AUTOSAR XML (schema 00050)
package /IBNvBlkSWC_0
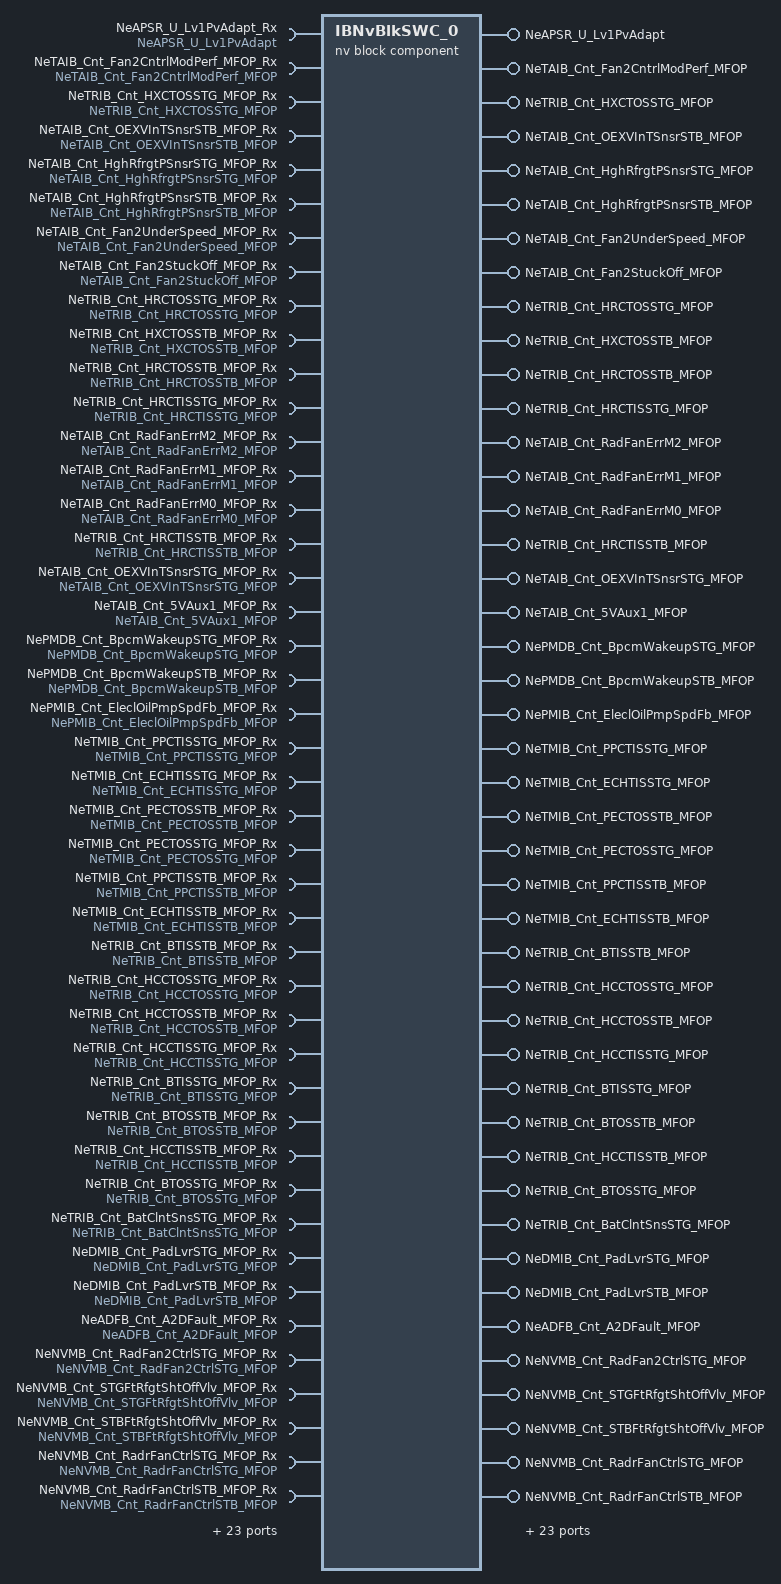
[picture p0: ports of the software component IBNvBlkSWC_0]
  nv block sw component type IBNvBlkSWC_0
    provide port NeAPSR_U_Lv1PvAdapt: nv-provide-com-spec{ram-block-init-value=Value:0, rom-block-init-value=Value:0, variable=NeAPSR_U_Lv1PvAdapt}, provided-interface=NeAPSR_U_Lv1PvAdapt
    require port NeAPSR_U_Lv1PvAdapt_Rx: nv-require-com-spec{init-value=Value:0, variable=NeAPSR_U_Lv1PvAdapt}, required-interface=NeAPSR_U_Lv1PvAdapt
    provide port NeTAIB_Cnt_Fan2CntrlModPerf_MFOP: nv-provide-com-spec{ram-block-init-value=Value:0, rom-block-init-value=Value:0, variable=NeTAIB_Cnt_Fan2CntrlModPerf_MFOP}, provided-interface=NeTAIB_Cnt_Fan2CntrlModPerf_MFOP
    require port NeTAIB_Cnt_Fan2CntrlModPerf_MFOP_Rx: nv-require-com-spec{init-value=Value:0, variable=NeTAIB_Cnt_Fan2CntrlModPerf_MFOP}, required-interface=NeTAIB_Cnt_Fan2CntrlModPerf_MFOP
    provide port NeTRIB_Cnt_HXCTOSSTG_MFOP: nv-provide-com-spec{ram-block-init-value=Value:0, rom-block-init-value=Value:0, variable=NeTRIB_Cnt_HXCTOSSTG_MFOP}, provided-interface=NeTRIB_Cnt_HXCTOSSTG_MFOP
    require port NeTRIB_Cnt_HXCTOSSTG_MFOP_Rx: nv-require-com-spec{init-value=Value:0, variable=NeTRIB_Cnt_HXCTOSSTG_MFOP}, required-interface=NeTRIB_Cnt_HXCTOSSTG_MFOP
    provide port NeTAIB_Cnt_OEXVInTSnsrSTB_MFOP: nv-provide-com-spec{ram-block-init-value=Value:0, rom-block-init-value=Value:0, variable=NeTAIB_Cnt_OEXVInTSnsrSTB_MFOP}, provided-interface=NeTAIB_Cnt_OEXVInTSnsrSTB_MFOP
    require port NeTAIB_Cnt_OEXVInTSnsrSTB_MFOP_Rx: nv-require-com-spec{init-value=Value:0, variable=NeTAIB_Cnt_OEXVInTSnsrSTB_MFOP}, required-interface=NeTAIB_Cnt_OEXVInTSnsrSTB_MFOP
    provide port NeTAIB_Cnt_HghRfrgtPSnsrSTG_MFOP: nv-provide-com-spec{ram-block-init-value=Value:0, rom-block-init-value=Value:0, variable=NeTAIB_Cnt_HghRfrgtPSnsrSTG_MFOP}, provided-interface=NeTAIB_Cnt_HghRfrgtPSnsrSTG_MFOP
    require port NeTAIB_Cnt_HghRfrgtPSnsrSTG_MFOP_Rx: nv-require-com-spec{init-value=Value:0, variable=NeTAIB_Cnt_HghRfrgtPSnsrSTG_MFOP}, required-interface=NeTAIB_Cnt_HghRfrgtPSnsrSTG_MFOP
    provide port NeTAIB_Cnt_HghRfrgtPSnsrSTB_MFOP: nv-provide-com-spec{ram-block-init-value=Value:0, rom-block-init-value=Value:0, variable=NeTAIB_Cnt_HghRfrgtPSnsrSTB_MFOP}, provided-interface=NeTAIB_Cnt_HghRfrgtPSnsrSTB_MFOP
    require port NeTAIB_Cnt_HghRfrgtPSnsrSTB_MFOP_Rx: nv-require-com-spec{init-value=Value:0, variable=NeTAIB_Cnt_HghRfrgtPSnsrSTB_MFOP}, required-interface=NeTAIB_Cnt_HghRfrgtPSnsrSTB_MFOP
    provide port NeTAIB_Cnt_Fan2UnderSpeed_MFOP: nv-provide-com-spec{ram-block-init-value=Value:0, rom-block-init-value=Value:0, variable=NeTAIB_Cnt_Fan2UnderSpeed_MFOP}, provided-interface=NeTAIB_Cnt_Fan2UnderSpeed_MFOP
    require port NeTAIB_Cnt_Fan2UnderSpeed_MFOP_Rx: nv-require-com-spec{init-value=Value:0, variable=NeTAIB_Cnt_Fan2UnderSpeed_MFOP}, required-interface=NeTAIB_Cnt_Fan2UnderSpeed_MFOP
    provide port NeTAIB_Cnt_Fan2StuckOff_MFOP: nv-provide-com-spec{ram-block-init-value=Value:0, rom-block-init-value=Value:0, variable=NeTAIB_Cnt_Fan2StuckOff_MFOP}, provided-interface=NeTAIB_Cnt_Fan2StuckOff_MFOP
    require port NeTAIB_Cnt_Fan2StuckOff_MFOP_Rx: nv-require-com-spec{init-value=Value:0, variable=NeTAIB_Cnt_Fan2StuckOff_MFOP}, required-interface=NeTAIB_Cnt_Fan2StuckOff_MFOP
    provide port NeTRIB_Cnt_HRCTOSSTG_MFOP: nv-provide-com-spec{ram-block-init-value=Value:0, rom-block-init-value=Value:0, variable=NeTRIB_Cnt_HRCTOSSTG_MFOP}, provided-interface=NeTRIB_Cnt_HRCTOSSTG_MFOP
    require port NeTRIB_Cnt_HRCTOSSTG_MFOP_Rx: nv-require-com-spec{init-value=Value:0, variable=NeTRIB_Cnt_HRCTOSSTG_MFOP}, required-interface=NeTRIB_Cnt_HRCTOSSTG_MFOP
    provide port NeTRIB_Cnt_HXCTOSSTB_MFOP: nv-provide-com-spec{ram-block-init-value=Value:0, rom-block-init-value=Value:0, variable=NeTRIB_Cnt_HXCTOSSTB_MFOP}, provided-interface=NeTRIB_Cnt_HXCTOSSTB_MFOP
    require port NeTRIB_Cnt_HXCTOSSTB_MFOP_Rx: nv-require-com-spec{init-value=Value:0, variable=NeTRIB_Cnt_HXCTOSSTB_MFOP}, required-interface=NeTRIB_Cnt_HXCTOSSTB_MFOP
    provide port NeTRIB_Cnt_HRCTOSSTB_MFOP: nv-provide-com-spec{ram-block-init-value=Value:0, rom-block-init-value=Value:0, variable=NeTRIB_Cnt_HRCTOSSTB_MFOP}, provided-interface=NeTRIB_Cnt_HRCTOSSTB_MFOP
    require port NeTRIB_Cnt_HRCTOSSTB_MFOP_Rx: nv-require-com-spec{init-value=Value:0, variable=NeTRIB_Cnt_HRCTOSSTB_MFOP}, required-interface=NeTRIB_Cnt_HRCTOSSTB_MFOP
    provide port NeTRIB_Cnt_HRCTISSTG_MFOP: nv-provide-com-spec{ram-block-init-value=Value:0, rom-block-init-value=Value:0, variable=NeTRIB_Cnt_HRCTISSTG_MFOP}, provided-interface=NeTRIB_Cnt_HRCTISSTG_MFOP
    require port NeTRIB_Cnt_HRCTISSTG_MFOP_Rx: nv-require-com-spec{init-value=Value:0, variable=NeTRIB_Cnt_HRCTISSTG_MFOP}, required-interface=NeTRIB_Cnt_HRCTISSTG_MFOP
    provide port NeTAIB_Cnt_RadFanErrM2_MFOP: nv-provide-com-spec{ram-block-init-value=Value:0, rom-block-init-value=Value:0, variable=NeTAIB_Cnt_RadFanErrM2_MFOP}, provided-interface=NeTAIB_Cnt_RadFanErrM2_MFOP
    require port NeTAIB_Cnt_RadFanErrM2_MFOP_Rx: nv-require-com-spec{init-value=Value:0, variable=NeTAIB_Cnt_RadFanErrM2_MFOP}, required-interface=NeTAIB_Cnt_RadFanErrM2_MFOP
    provide port NeTAIB_Cnt_RadFanErrM1_MFOP: nv-provide-com-spec{ram-block-init-value=Value:0, rom-block-init-value=Value:0, variable=NeTAIB_Cnt_RadFanErrM1_MFOP}, provided-interface=NeTAIB_Cnt_RadFanErrM1_MFOP
    require port NeTAIB_Cnt_RadFanErrM1_MFOP_Rx: nv-require-com-spec{init-value=Value:0, variable=NeTAIB_Cnt_RadFanErrM1_MFOP}, required-interface=NeTAIB_Cnt_RadFanErrM1_MFOP
    provide port NeTAIB_Cnt_RadFanErrM0_MFOP: nv-provide-com-spec{ram-block-init-value=Value:0, rom-block-init-value=Value:0, variable=NeTAIB_Cnt_RadFanErrM0_MFOP}, provided-interface=NeTAIB_Cnt_RadFanErrM0_MFOP
    require port NeTAIB_Cnt_RadFanErrM0_MFOP_Rx: nv-require-com-spec{init-value=Value:0, variable=NeTAIB_Cnt_RadFanErrM0_MFOP}, required-interface=NeTAIB_Cnt_RadFanErrM0_MFOP
    provide port NeTRIB_Cnt_HRCTISSTB_MFOP: nv-provide-com-spec{ram-block-init-value=Value:0, rom-block-init-value=Value:0, variable=NeTRIB_Cnt_HRCTISSTB_MFOP}, provided-interface=NeTRIB_Cnt_HRCTISSTB_MFOP
    require port NeTRIB_Cnt_HRCTISSTB_MFOP_Rx: nv-require-com-spec{init-value=Value:0, variable=NeTRIB_Cnt_HRCTISSTB_MFOP}, required-interface=NeTRIB_Cnt_HRCTISSTB_MFOP
    provide port NeTAIB_Cnt_OEXVInTSnsrSTG_MFOP: nv-provide-com-spec{ram-block-init-value=Value:0, rom-block-init-value=Value:0, variable=NeTAIB_Cnt_OEXVInTSnsrSTG_MFOP}, provided-interface=NeTAIB_Cnt_OEXVInTSnsrSTG_MFOP
    require port NeTAIB_Cnt_OEXVInTSnsrSTG_MFOP_Rx: nv-require-com-spec{init-value=Value:0, variable=NeTAIB_Cnt_OEXVInTSnsrSTG_MFOP}, required-interface=NeTAIB_Cnt_OEXVInTSnsrSTG_MFOP
    provide port NeTAIB_Cnt_5VAux1_MFOP: nv-provide-com-spec{ram-block-init-value=Value:0, rom-block-init-value=Value:0, variable=NeTAIB_Cnt_5VAux1_MFOP}, provided-interface=NeTAIB_Cnt_5VAux1_MFOP
    require port NeTAIB_Cnt_5VAux1_MFOP_Rx: nv-require-com-spec{init-value=Value:0, variable=NeTAIB_Cnt_5VAux1_MFOP}, required-interface=NeTAIB_Cnt_5VAux1_MFOP
    provide port NePMDB_Cnt_BpcmWakeupSTG_MFOP: nv-provide-com-spec{ram-block-init-value=Value:0, rom-block-init-value=Value:0, variable=NePMDB_Cnt_BpcmWakeupSTG_MFOP}, provided-interface=NePMDB_Cnt_BpcmWakeupSTG_MFOP
    require port NePMDB_Cnt_BpcmWakeupSTG_MFOP_Rx: nv-require-com-spec{init-value=Value:0, variable=NePMDB_Cnt_BpcmWakeupSTG_MFOP}, required-interface=NePMDB_Cnt_BpcmWakeupSTG_MFOP
    provide port NePMDB_Cnt_BpcmWakeupSTB_MFOP: nv-provide-com-spec{ram-block-init-value=Value:0, rom-block-init-value=Value:0, variable=NePMDB_Cnt_BpcmWakeupSTB_MFOP}, provided-interface=NePMDB_Cnt_BpcmWakeupSTB_MFOP
    require port NePMDB_Cnt_BpcmWakeupSTB_MFOP_Rx: nv-require-com-spec{init-value=Value:0, variable=NePMDB_Cnt_BpcmWakeupSTB_MFOP}, required-interface=NePMDB_Cnt_BpcmWakeupSTB_MFOP
    provide port NePMIB_Cnt_EleclOilPmpSpdFb_MFOP: nv-provide-com-spec{ram-block-init-value=Value:0, rom-block-init-value=Value:0, variable=NePMIB_Cnt_EleclOilPmpSpdFb_MFOP}, provided-interface=NePMIB_Cnt_EleclOilPmpSpdFb_MFOP
    require port NePMIB_Cnt_EleclOilPmpSpdFb_MFOP_Rx: nv-require-com-spec{init-value=Value:0, variable=NePMIB_Cnt_EleclOilPmpSpdFb_MFOP}, required-interface=NePMIB_Cnt_EleclOilPmpSpdFb_MFOP
    provide port NeTMIB_Cnt_PPCTISSTG_MFOP: nv-provide-com-spec{ram-block-init-value=Value:0, rom-block-init-value=Value:0, variable=NeTMIB_Cnt_PPCTISSTG_MFOP}, provided-interface=NeTMIB_Cnt_PPCTISSTG_MFOP
    require port NeTMIB_Cnt_PPCTISSTG_MFOP_Rx: nv-require-com-spec{init-value=Value:0, variable=NeTMIB_Cnt_PPCTISSTG_MFOP}, required-interface=NeTMIB_Cnt_PPCTISSTG_MFOP
    provide port NeTMIB_Cnt_ECHTISSTG_MFOP: nv-provide-com-spec{ram-block-init-value=Value:0, rom-block-init-value=Value:0, variable=NeTMIB_Cnt_ECHTISSTG_MFOP}, provided-interface=NeTMIB_Cnt_ECHTISSTG_MFOP
    require port NeTMIB_Cnt_ECHTISSTG_MFOP_Rx: nv-require-com-spec{init-value=Value:0, variable=NeTMIB_Cnt_ECHTISSTG_MFOP}, required-interface=NeTMIB_Cnt_ECHTISSTG_MFOP
    provide port NeTMIB_Cnt_PECTOSSTB_MFOP: nv-provide-com-spec{ram-block-init-value=Value:0, rom-block-init-value=Value:0, variable=NeTMIB_Cnt_PECTOSSTB_MFOP}, provided-interface=NeTMIB_Cnt_PECTOSSTB_MFOP
    require port NeTMIB_Cnt_PECTOSSTB_MFOP_Rx: nv-require-com-spec{init-value=Value:0, variable=NeTMIB_Cnt_PECTOSSTB_MFOP}, required-interface=NeTMIB_Cnt_PECTOSSTB_MFOP
    provide port NeTMIB_Cnt_PECTOSSTG_MFOP: nv-provide-com-spec{ram-block-init-value=Value:0, rom-block-init-value=Value:0, variable=NeTMIB_Cnt_PECTOSSTG_MFOP}, provided-interface=NeTMIB_Cnt_PECTOSSTG_MFOP
    require port NeTMIB_Cnt_PECTOSSTG_MFOP_Rx: nv-require-com-spec{init-value=Value:0, variable=NeTMIB_Cnt_PECTOSSTG_MFOP}, required-interface=NeTMIB_Cnt_PECTOSSTG_MFOP
    provide port NeTMIB_Cnt_PPCTISSTB_MFOP: nv-provide-com-spec{ram-block-init-value=Value:0, rom-block-init-value=Value:0, variable=NeTMIB_Cnt_PPCTISSTB_MFOP}, provided-interface=NeTMIB_Cnt_PPCTISSTB_MFOP
    require port NeTMIB_Cnt_PPCTISSTB_MFOP_Rx: nv-require-com-spec{init-value=Value:0, variable=NeTMIB_Cnt_PPCTISSTB_MFOP}, required-interface=NeTMIB_Cnt_PPCTISSTB_MFOP
    provide port NeTMIB_Cnt_ECHTISSTB_MFOP: nv-provide-com-spec{ram-block-init-value=Value:0, rom-block-init-value=Value:0, variable=NeTMIB_Cnt_ECHTISSTB_MFOP}, provided-interface=NeTMIB_Cnt_ECHTISSTB_MFOP
    require port NeTMIB_Cnt_ECHTISSTB_MFOP_Rx: nv-require-com-spec{init-value=Value:0, variable=NeTMIB_Cnt_ECHTISSTB_MFOP}, required-interface=NeTMIB_Cnt_ECHTISSTB_MFOP
    provide port NeTRIB_Cnt_BTISSTB_MFOP: nv-provide-com-spec{ram-block-init-value=Value:0, rom-block-init-value=Value:0, variable=NeTRIB_Cnt_BTISSTB_MFOP}, provided-interface=NeTRIB_Cnt_BTISSTB_MFOP
    require port NeTRIB_Cnt_BTISSTB_MFOP_Rx: nv-require-com-spec{init-value=Value:0, variable=NeTRIB_Cnt_BTISSTB_MFOP}, required-interface=NeTRIB_Cnt_BTISSTB_MFOP
    provide port NeTRIB_Cnt_HCCTOSSTG_MFOP: nv-provide-com-spec{ram-block-init-value=Value:0, rom-block-init-value=Value:0, variable=NeTRIB_Cnt_HCCTOSSTG_MFOP}, provided-interface=NeTRIB_Cnt_HCCTOSSTG_MFOP
    require port NeTRIB_Cnt_HCCTOSSTG_MFOP_Rx: nv-require-com-spec{init-value=Value:0, variable=NeTRIB_Cnt_HCCTOSSTG_MFOP}, required-interface=NeTRIB_Cnt_HCCTOSSTG_MFOP
    provide port NeTRIB_Cnt_HCCTOSSTB_MFOP: nv-provide-com-spec{ram-block-init-value=Value:0, rom-block-init-value=Value:0, variable=NeTRIB_Cnt_HCCTOSSTB_MFOP}, provided-interface=NeTRIB_Cnt_HCCTOSSTB_MFOP
    require port NeTRIB_Cnt_HCCTOSSTB_MFOP_Rx: nv-require-com-spec{init-value=Value:0, variable=NeTRIB_Cnt_HCCTOSSTB_MFOP}, required-interface=NeTRIB_Cnt_HCCTOSSTB_MFOP
    provide port NeTRIB_Cnt_HCCTISSTG_MFOP: nv-provide-com-spec{ram-block-init-value=Value:0, rom-block-init-value=Value:0, variable=NeTRIB_Cnt_HCCTISSTG_MFOP}, provided-interface=NeTRIB_Cnt_HCCTISSTG_MFOP
    require port NeTRIB_Cnt_HCCTISSTG_MFOP_Rx: nv-require-com-spec{init-value=Value:0, variable=NeTRIB_Cnt_HCCTISSTG_MFOP}, required-interface=NeTRIB_Cnt_HCCTISSTG_MFOP
    provide port NeTRIB_Cnt_BTISSTG_MFOP: nv-provide-com-spec{ram-block-init-value=Value:0, rom-block-init-value=Value:0, variable=NeTRIB_Cnt_BTISSTG_MFOP}, provided-interface=NeTRIB_Cnt_BTISSTG_MFOP
    require port NeTRIB_Cnt_BTISSTG_MFOP_Rx: nv-require-com-spec{init-value=Value:0, variable=NeTRIB_Cnt_BTISSTG_MFOP}, required-interface=NeTRIB_Cnt_BTISSTG_MFOP
    provide port NeTRIB_Cnt_BTOSSTB_MFOP: nv-provide-com-spec{ram-block-init-value=Value:0, rom-block-init-value=Value:0, variable=NeTRIB_Cnt_BTOSSTB_MFOP}, provided-interface=NeTRIB_Cnt_BTOSSTB_MFOP
    require port NeTRIB_Cnt_BTOSSTB_MFOP_Rx: nv-require-com-spec{init-value=Value:0, variable=NeTRIB_Cnt_BTOSSTB_MFOP}, required-interface=NeTRIB_Cnt_BTOSSTB_MFOP
    provide port NeTRIB_Cnt_HCCTISSTB_MFOP: nv-provide-com-spec{ram-block-init-value=Value:0, rom-block-init-value=Value:0, variable=NeTRIB_Cnt_HCCTISSTB_MFOP}, provided-interface=NeTRIB_Cnt_HCCTISSTB_MFOP
    require port NeTRIB_Cnt_HCCTISSTB_MFOP_Rx: nv-require-com-spec{init-value=Value:0, variable=NeTRIB_Cnt_HCCTISSTB_MFOP}, required-interface=NeTRIB_Cnt_HCCTISSTB_MFOP
    provide port NeTRIB_Cnt_BTOSSTG_MFOP: nv-provide-com-spec{ram-block-init-value=Value:0, rom-block-init-value=Value:0, variable=NeTRIB_Cnt_BTOSSTG_MFOP}, provided-interface=NeTRIB_Cnt_BTOSSTG_MFOP
    require port NeTRIB_Cnt_BTOSSTG_MFOP_Rx: nv-require-com-spec{init-value=Value:0, variable=NeTRIB_Cnt_BTOSSTG_MFOP}, required-interface=NeTRIB_Cnt_BTOSSTG_MFOP
    provide port NeTRIB_Cnt_BatClntSnsSTG_MFOP: nv-provide-com-spec{ram-block-init-value=Value:0, rom-block-init-value=Value:0, variable=NeTRIB_Cnt_BatClntSnsSTG_MFOP}, provided-interface=NeTRIB_Cnt_BatClntSnsSTG_MFOP
    require port NeTRIB_Cnt_BatClntSnsSTG_MFOP_Rx: nv-require-com-spec{init-value=Value:0, variable=NeTRIB_Cnt_BatClntSnsSTG_MFOP}, required-interface=NeTRIB_Cnt_BatClntSnsSTG_MFOP
    provide port NeDMIB_Cnt_PadLvrSTG_MFOP: nv-provide-com-spec{ram-block-init-value=Value:0, rom-block-init-value=Value:0, variable=NeDMIB_Cnt_PadLvrSTG_MFOP}, provided-interface=NeDMIB_Cnt_PadLvrSTG_MFOP
    require port NeDMIB_Cnt_PadLvrSTG_MFOP_Rx: nv-require-com-spec{init-value=Value:0, variable=NeDMIB_Cnt_PadLvrSTG_MFOP}, required-interface=NeDMIB_Cnt_PadLvrSTG_MFOP
    provide port NeDMIB_Cnt_PadLvrSTB_MFOP: nv-provide-com-spec{ram-block-init-value=Value:0, rom-block-init-value=Value:0, variable=NeDMIB_Cnt_PadLvrSTB_MFOP}, provided-interface=NeDMIB_Cnt_PadLvrSTB_MFOP
    require port NeDMIB_Cnt_PadLvrSTB_MFOP_Rx: nv-require-com-spec{init-value=Value:0, variable=NeDMIB_Cnt_PadLvrSTB_MFOP}, required-interface=NeDMIB_Cnt_PadLvrSTB_MFOP
    provide port NeADFB_Cnt_A2DFault_MFOP: nv-provide-com-spec{ram-block-init-value=Value:0, rom-block-init-value=Value:0, variable=NeADFB_Cnt_A2DFault_MFOP}, provided-interface=NeADFB_Cnt_A2DFault_MFOP
    require port NeADFB_Cnt_A2DFault_MFOP_Rx: nv-require-com-spec{init-value=Value:0, variable=NeADFB_Cnt_A2DFault_MFOP}, required-interface=NeADFB_Cnt_A2DFault_MFOP
    provide port NeNVMB_Cnt_RadFan2CtrlSTG_MFOP: nv-provide-com-spec{ram-block-init-value=Value:0, rom-block-init-value=Value:0, variable=NeNVMB_Cnt_RadFan2CtrlSTG_MFOP}, provided-interface=NeNVMB_Cnt_RadFan2CtrlSTG_MFOP
    require port NeNVMB_Cnt_RadFan2CtrlSTG_MFOP_Rx: nv-require-com-spec{init-value=Value:0, variable=NeNVMB_Cnt_RadFan2CtrlSTG_MFOP}, required-interface=NeNVMB_Cnt_RadFan2CtrlSTG_MFOP
    provide port NeNVMB_Cnt_STGFtRfgtShtOffVlv_MFOP: nv-provide-com-spec{ram-block-init-value=Value:0, rom-block-init-value=Value:0, variable=NeNVMB_Cnt_STGFtRfgtShtOffVlv_MFOP}, provided-interface=NeNVMB_Cnt_STGFtRfgtShtOffVlv_MFOP
    require port NeNVMB_Cnt_STGFtRfgtShtOffVlv_MFOP_Rx: nv-require-com-spec{init-value=Value:0, variable=NeNVMB_Cnt_STGFtRfgtShtOffVlv_MFOP}, required-interface=NeNVMB_Cnt_STGFtRfgtShtOffVlv_MFOP
    provide port NeNVMB_Cnt_STBFtRfgtShtOffVlv_MFOP: nv-provide-com-spec{ram-block-init-value=Value:0, rom-block-init-value=Value:0, variable=NeNVMB_Cnt_STBFtRfgtShtOffVlv_MFOP}, provided-interface=NeNVMB_Cnt_STBFtRfgtShtOffVlv_MFOP
    require port NeNVMB_Cnt_STBFtRfgtShtOffVlv_MFOP_Rx: nv-require-com-spec{init-value=Value:0, variable=NeNVMB_Cnt_STBFtRfgtShtOffVlv_MFOP}, required-interface=NeNVMB_Cnt_STBFtRfgtShtOffVlv_MFOP
    provide port NeNVMB_Cnt_RadrFanCtrlSTG_MFOP: nv-provide-com-spec{ram-block-init-value=Value:0, rom-block-init-value=Value:0, variable=NeNVMB_Cnt_RadrFanCtrlSTG_MFOP}, provided-interface=NeNVMB_Cnt_RadrFanCtrlSTG_MFOP
    require port NeNVMB_Cnt_RadrFanCtrlSTG_MFOP_Rx: nv-require-com-spec{init-value=Value:0, variable=NeNVMB_Cnt_RadrFanCtrlSTG_MFOP}, required-interface=NeNVMB_Cnt_RadrFanCtrlSTG_MFOP
    provide port NeNVMB_Cnt_RadrFanCtrlSTB_MFOP: nv-provide-com-spec{ram-block-init-value=Value:0, rom-block-init-value=Value:0, variable=NeNVMB_Cnt_RadrFanCtrlSTB_MFOP}, provided-interface=NeNVMB_Cnt_RadrFanCtrlSTB_MFOP
    require port NeNVMB_Cnt_RadrFanCtrlSTB_MFOP_Rx: nv-require-com-spec{init-value=Value:0, variable=NeNVMB_Cnt_RadrFanCtrlSTB_MFOP}, required-interface=NeNVMB_Cnt_RadrFanCtrlSTB_MFOP
    provide port NeNVMB_Cnt_RadFan2CtrlSTB_MFOP: nv-provide-com-spec{ram-block-init-value=Value:0, rom-block-init-value=Value:0, variable=NeNVMB_Cnt_RadFan2CtrlSTB_MFOP}, provided-interface=NeNVMB_Cnt_RadFan2CtrlSTB_MFOP
    require port NeNVMB_Cnt_RadFan2CtrlSTB_MFOP_Rx: nv-require-com-spec{init-value=Value:0, variable=NeNVMB_Cnt_RadFan2CtrlSTB_MFOP}, required-interface=NeNVMB_Cnt_RadFan2CtrlSTB_MFOP
    provide port NeNVMB_Cnt_RadFan2CtrlOC_MFOP: nv-provide-com-spec{ram-block-init-value=Value:0, rom-block-init-value=Value:0, variable=NeNVMB_Cnt_RadFan2CtrlOC_MFOP}, provided-interface=NeNVMB_Cnt_RadFan2CtrlOC_MFOP
    require port NeNVMB_Cnt_RadFan2CtrlOC_MFOP_Rx: nv-require-com-spec{init-value=Value:0, variable=NeNVMB_Cnt_RadFan2CtrlOC_MFOP}, required-interface=NeNVMB_Cnt_RadFan2CtrlOC_MFOP
    provide port NeNVMB_Cnt_ePTWakeUpEnblOC_MFOP: nv-provide-com-spec{ram-block-init-value=Value:0, rom-block-init-value=Value:0, variable=NeNVMB_Cnt_ePTWakeUpEnblOC_MFOP}, provided-interface=NeNVMB_Cnt_ePTWakeUpEnblOC_MFOP
    require port NeNVMB_Cnt_ePTWakeUpEnblOC_MFOP_Rx: nv-require-com-spec{init-value=Value:0, variable=NeNVMB_Cnt_ePTWakeUpEnblOC_MFOP}, required-interface=NeNVMB_Cnt_ePTWakeUpEnblOC_MFOP
    provide port NeNVMB_Cnt_ePTWakeUpEnblSTB_MFOP: nv-provide-com-spec{ram-block-init-value=Value:0, rom-block-init-value=Value:0, variable=NeNVMB_Cnt_ePTWakeUpEnblSTB_MFOP}, provided-interface=NeNVMB_Cnt_ePTWakeUpEnblSTB_MFOP
    require port NeNVMB_Cnt_ePTWakeUpEnblSTB_MFOP_Rx: nv-require-com-spec{init-value=Value:0, variable=NeNVMB_Cnt_ePTWakeUpEnblSTB_MFOP}, required-interface=NeNVMB_Cnt_ePTWakeUpEnblSTB_MFOP
    provide port NeNVMB_Cnt_ePTWakeUpEnblSTG_MFOP: nv-provide-com-spec{ram-block-init-value=Value:0, rom-block-init-value=Value:0, variable=NeNVMB_Cnt_ePTWakeUpEnblSTG_MFOP}, provided-interface=NeNVMB_Cnt_ePTWakeUpEnblSTG_MFOP
    require port NeNVMB_Cnt_ePTWakeUpEnblSTG_MFOP_Rx: nv-require-com-spec{init-value=Value:0, variable=NeNVMB_Cnt_ePTWakeUpEnblSTG_MFOP}, required-interface=NeNVMB_Cnt_ePTWakeUpEnblSTG_MFOP
    provide port NeNVMB_Cnt_FtRfgtShtOffVlvOC_MFOP: nv-provide-com-spec{ram-block-init-value=Value:0, rom-block-init-value=Value:0, variable=NeNVMB_Cnt_FtRfgtShtOffVlvOC_MFOP}, provided-interface=NeNVMB_Cnt_FtRfgtShtOffVlvOC_MFOP
    require port NeNVMB_Cnt_FtRfgtShtOffVlvOC_MFOP_Rx: nv-require-com-spec{init-value=Value:0, variable=NeNVMB_Cnt_FtRfgtShtOffVlvOC_MFOP}, required-interface=NeNVMB_Cnt_FtRfgtShtOffVlvOC_MFOP
    provide port NeNVMB_Cnt_ThermSysEnbl_MFOP: nv-provide-com-spec{ram-block-init-value=Value:0, rom-block-init-value=Value:0, variable=NeNVMB_Cnt_ThermSysEnbl_MFOP}, provided-interface=NeNVMB_Cnt_ThermSysEnbl_MFOP
    require port NeNVMB_Cnt_ThermSysEnbl_MFOP_Rx: nv-require-com-spec{init-value=Value:0, variable=NeNVMB_Cnt_ThermSysEnbl_MFOP}, required-interface=NeNVMB_Cnt_ThermSysEnbl_MFOP
    provide port NeNVMB_Cnt_RadrFanCtrlOC_MFOP: nv-provide-com-spec{ram-block-init-value=Value:0, rom-block-init-value=Value:0, variable=NeNVMB_Cnt_RadrFanCtrlOC_MFOP}, provided-interface=NeNVMB_Cnt_RadrFanCtrlOC_MFOP
    require port NeNVMB_Cnt_RadrFanCtrlOC_MFOP_Rx: nv-require-com-spec{init-value=Value:0, variable=NeNVMB_Cnt_RadrFanCtrlOC_MFOP}, required-interface=NeNVMB_Cnt_RadrFanCtrlOC_MFOP
    provide port NeBSWR_e_ShutOffPathTestStatus_prev: nv-provide-com-spec{ram-block-init-value=Value:0, rom-block-init-value=Value:0, variable=NeBSWR_e_ShutOffPathTestStatus_prev}, provided-interface=NeBSWR_e_ShutOffPathTestStatus_prev
    require port NeBSWR_e_ShutOffPathTestStatus_prev_Rx: nv-require-com-spec{init-value=Value:0, variable=NeBSWR_e_ShutOffPathTestStatus_prev}, required-interface=NeBSWR_e_ShutOffPathTestStatus_prev
    provide port NeSPT_SkippedOccurenceCounter: nv-provide-com-spec{ram-block-init-value=Value:0, rom-block-init-value=Value:0, variable=NeSPT_SkippedOccurenceCounter}, provided-interface=NeSPT_SkippedOccurenceCounter
    require port NeSPT_SkippedOccurenceCounter_Rx: nv-require-com-spec{init-value=Value:0, variable=NeSPT_SkippedOccurenceCounter}, required-interface=NeSPT_SkippedOccurenceCounter
    provide port NeSPT_AttemptsCounter: nv-provide-com-spec{ram-block-init-value=Value:0, rom-block-init-value=Value:0, variable=NeSPT_AttemptsCounter}, provided-interface=NeSPT_AttemptsCounter
    require port NeSPT_AttemptsCounter_Rx: nv-require-com-spec{init-value=Value:0, variable=NeSPT_AttemptsCounter}, required-interface=NeSPT_AttemptsCounter
    provide port AeAPSR_U_Pvs1MaxValue: nv-provide-com-spec{ram-block-init-value=Value:0, rom-block-init-value=Value:0, variable=AeAPSR_U_Pvs1MaxValue}, provided-interface=AeAPSR_U_Pvs1MaxValue
    require port AeAPSR_U_Pvs1MaxValue_Rx: nv-require-com-spec{init-value=Value:0, variable=AeAPSR_U_Pvs1MaxValue}, required-interface=AeAPSR_U_Pvs1MaxValue
    provide port AeAPSR_U_Pvs1MinValue: nv-provide-com-spec{ram-block-init-value=Value:0, rom-block-init-value=Value:0, variable=AeAPSR_U_Pvs1MinValue}, provided-interface=AeAPSR_U_Pvs1MinValue
    require port AeAPSR_U_Pvs1MinValue_Rx: nv-require-com-spec{init-value=Value:0, variable=AeAPSR_U_Pvs1MinValue}, required-interface=AeAPSR_U_Pvs1MinValue
    provide port AeAPSR_U_Pvs2MaxValue: nv-provide-com-spec{ram-block-init-value=Value:0, rom-block-init-value=Value:0, variable=AeAPSR_U_Pvs2MaxValue}, provided-interface=AeAPSR_U_Pvs2MaxValue
    require port AeAPSR_U_Pvs2MaxValue_Rx: nv-require-com-spec{init-value=Value:0, variable=AeAPSR_U_Pvs2MaxValue}, required-interface=AeAPSR_U_Pvs2MaxValue
    provide port AeAPSR_U_Pvs2MinValue: nv-provide-com-spec{ram-block-init-value=Value:0, rom-block-init-value=Value:0, variable=AeAPSR_U_Pvs2MinValue}, provided-interface=AeAPSR_U_Pvs2MinValue
    require port AeAPSR_U_Pvs2MinValue_Rx: nv-require-com-spec{init-value=Value:0, variable=AeAPSR_U_Pvs2MinValue}, required-interface=AeAPSR_U_Pvs2MinValue
    provide port AeAPSR_b_Pv2MinTestNotCmplt: nv-provide-com-spec{ram-block-init-value=Value:0, rom-block-init-value=Value:0, variable=AeAPSR_b_Pv2MinTestNotCmplt}, provided-interface=AeAPSR_b_Pv2MinTestNotCmplt
    require port AeAPSR_b_Pv2MinTestNotCmplt_Rx: nv-require-com-spec{init-value=Value:0, variable=AeAPSR_b_Pv2MinTestNotCmplt}, required-interface=AeAPSR_b_Pv2MinTestNotCmplt
    provide port AeAPSR_b_Pv2MinTestFailed: nv-provide-com-spec{ram-block-init-value=Value:0, rom-block-init-value=Value:0, variable=AeAPSR_b_Pv2MinTestFailed}, provided-interface=AeAPSR_b_Pv2MinTestFailed
    require port AeAPSR_b_Pv2MinTestFailed_Rx: nv-require-com-spec{init-value=Value:0, variable=AeAPSR_b_Pv2MinTestFailed}, required-interface=AeAPSR_b_Pv2MinTestFailed
    provide port AeAPSR_b_Pv2MaxTestNotCmplt: nv-provide-com-spec{ram-block-init-value=Value:0, rom-block-init-value=Value:0, variable=AeAPSR_b_Pv2MaxTestNotCmplt}, provided-interface=AeAPSR_b_Pv2MaxTestNotCmplt
    require port AeAPSR_b_Pv2MaxTestNotCmplt_Rx: nv-require-com-spec{init-value=Value:0, variable=AeAPSR_b_Pv2MaxTestNotCmplt}, required-interface=AeAPSR_b_Pv2MaxTestNotCmplt
    provide port AeAPSR_b_Pv2MaxTestFailed: nv-provide-com-spec{ram-block-init-value=Value:0, rom-block-init-value=Value:0, variable=AeAPSR_b_Pv2MaxTestFailed}, provided-interface=AeAPSR_b_Pv2MaxTestFailed
    require port AeAPSR_b_Pv2MaxTestFailed_Rx: nv-require-com-spec{init-value=Value:0, variable=AeAPSR_b_Pv2MaxTestFailed}, required-interface=AeAPSR_b_Pv2MaxTestFailed
    provide port AeAPSR_b_Pv1MinTestNotCmplt: nv-provide-com-spec{ram-block-init-value=Value:0, rom-block-init-value=Value:0, variable=AeAPSR_b_Pv1MinTestNotCmplt}, provided-interface=AeAPSR_b_Pv1MinTestNotCmplt
    require port AeAPSR_b_Pv1MinTestNotCmplt_Rx: nv-require-com-spec{init-value=Value:0, variable=AeAPSR_b_Pv1MinTestNotCmplt}, required-interface=AeAPSR_b_Pv1MinTestNotCmplt
    provide port AeAPSR_b_Pv1MinTestFailed: nv-provide-com-spec{ram-block-init-value=Value:0, rom-block-init-value=Value:0, variable=AeAPSR_b_Pv1MinTestFailed}, provided-interface=AeAPSR_b_Pv1MinTestFailed
    require port AeAPSR_b_Pv1MinTestFailed_Rx: nv-require-com-spec{init-value=Value:0, variable=AeAPSR_b_Pv1MinTestFailed}, required-interface=AeAPSR_b_Pv1MinTestFailed
    provide port AeAPSR_b_Pv1MaxTestNotCmplt: nv-provide-com-spec{ram-block-init-value=Value:0, rom-block-init-value=Value:0, variable=AeAPSR_b_Pv1MaxTestNotCmplt}, provided-interface=AeAPSR_b_Pv1MaxTestNotCmplt
    require port AeAPSR_b_Pv1MaxTestNotCmplt_Rx: nv-require-com-spec{init-value=Value:0, variable=AeAPSR_b_Pv1MaxTestNotCmplt}, required-interface=AeAPSR_b_Pv1MaxTestNotCmplt
    provide port AeAPSR_b_Pv1MaxTestFailed: nv-provide-com-spec{ram-block-init-value=Value:0, rom-block-init-value=Value:0, variable=AeAPSR_b_Pv1MaxTestFailed}, provided-interface=AeAPSR_b_Pv1MaxTestFailed
    require port AeAPSR_b_Pv1MaxTestFailed_Rx: nv-require-com-spec{init-value=Value:0, variable=AeAPSR_b_Pv1MaxTestFailed}, required-interface=AeAPSR_b_Pv1MaxTestFailed
    behavior IB_NvBlkSWC_0: data-type-mapping=NVM_DataMappingSet, handle-termination-and-restart=NO-SUPPORT
      12 x data received event:
        DataReceivedEvent_AeAPSR_U_Pvs1MaxValue: start-on-event=RE_AeAPSR_U_Pvs1MaxValue, data=AeAPSR_U_Pvs1MaxValue_Rx.AeAPSR_U_Pvs1MaxValue
        DataReceivedEvent_AeAPSR_U_Pvs1MinValue: start-on-event=RE_AeAPSR_U_Pvs1MinValue, data=AeAPSR_U_Pvs1MinValue_Rx.AeAPSR_U_Pvs1MinValue
        DataReceivedEvent_AeAPSR_U_Pvs2MaxValue: start-on-event=RE_AeAPSR_U_Pvs2MaxValue, data=AeAPSR_U_Pvs2MaxValue_Rx.AeAPSR_U_Pvs2MaxValue
        DataReceivedEvent_AeAPSR_U_Pvs2MinValue: start-on-event=RE_AeAPSR_U_Pvs2MinValue, data=AeAPSR_U_Pvs2MinValue_Rx.AeAPSR_U_Pvs2MinValue
        DataReceivedEvent_AeAPSR_b_Pv2MinTestNotCmplt: start-on-event=RE_AeAPSR_b_Pv2MinTestNotCmplt, data=AeAPSR_b_Pv2MinTestNotCmplt_Rx.AeAPSR_b_Pv2MinTestNotCmplt
        DataReceivedEvent_AeAPSR_b_Pv2MinTestFailed: start-on-event=RE_AeAPSR_b_Pv2MinTestFailed, data=AeAPSR_b_Pv2MinTestFailed_Rx.AeAPSR_b_Pv2MinTestFailed
        DataReceivedEvent_AeAPSR_b_Pv2MaxTestNotCmplt: start-on-event=RE_AeAPSR_b_Pv2MaxTestNotCmplt, data=AeAPSR_b_Pv2MaxTestNotCmplt_Rx.AeAPSR_b_Pv2MaxTestNotCmplt
        DataReceivedEvent_AeAPSR_b_Pv2MaxTestFailed: start-on-event=RE_AeAPSR_b_Pv2MaxTestFailed, data=AeAPSR_b_Pv2MaxTestFailed_Rx.AeAPSR_b_Pv2MaxTestFailed
        DataReceivedEvent_AeAPSR_b_Pv1MinTestNotCmplt: start-on-event=RE_AeAPSR_b_Pv1MinTestNotCmplt, data=AeAPSR_b_Pv1MinTestNotCmplt_Rx.AeAPSR_b_Pv1MinTestNotCmplt
        DataReceivedEvent_AeAPSR_b_Pv1MinTestFailed: start-on-event=RE_AeAPSR_b_Pv1MinTestFailed, data=AeAPSR_b_Pv1MinTestFailed_Rx.AeAPSR_b_Pv1MinTestFailed
        DataReceivedEvent_AeAPSR_b_Pv1MaxTestNotCmplt: start-on-event=RE_AeAPSR_b_Pv1MaxTestNotCmplt, data=AeAPSR_b_Pv1MaxTestNotCmplt_Rx.AeAPSR_b_Pv1MaxTestNotCmplt
        DataReceivedEvent_AeAPSR_b_Pv1MaxTestFailed: start-on-event=RE_AeAPSR_b_Pv1MaxTestFailed, data=AeAPSR_b_Pv1MaxTestFailed_Rx.AeAPSR_b_Pv1MaxTestFailed
      12 x runnable:
        RE_AeAPSR_U_Pvs1MaxValue
        RE_AeAPSR_U_Pvs1MinValue
        RE_AeAPSR_U_Pvs2MaxValue
        RE_AeAPSR_U_Pvs2MinValue
        RE_AeAPSR_b_Pv2MinTestNotCmplt
        RE_AeAPSR_b_Pv2MinTestFailed
        RE_AeAPSR_b_Pv2MaxTestNotCmplt
        RE_AeAPSR_b_Pv2MaxTestFailed
        RE_AeAPSR_b_Pv1MinTestNotCmplt
        RE_AeAPSR_b_Pv1MinTestFailed
        RE_AeAPSR_b_Pv1MaxTestNotCmplt
        RE_AeAPSR_b_Pv1MaxTestFailed
    nv block descriptor ExpendableNonVolatile_Descr_Core0: support-dirty-flag=true
      nv-block-data-mappings:
        {nv-ram-block-element=autosar-variable-in-impl-datatype={root-variable-data-prototype=ExpendableNonVolatile_RamBlock_Core0, target-data-prototype=ExpendableNonVolatile_Ram_Core0/NeAPSR_U_Lv1PvAdapt}, read-nv-data=NeAPSR_U_Lv1PvAdapt.NeAPSR_U_Lv1PvAdapt}
        {nv-ram-block-element=autosar-variable-in-impl-datatype={root-variable-data-prototype=ExpendableNonVolatile_RamBlock_Core0, target-data-prototype=ExpendableNonVolatile_Ram_Core0/NeAPSR_U_Lv1PvAdapt}, written-nv-data=NeAPSR_U_Lv1PvAdapt_Rx.NeAPSR_U_Lv1PvAdapt}
        {nv-ram-block-element=autosar-variable-in-impl-datatype={root-variable-data-prototype=ExpendableNonVolatile_RamBlock_Core0, target-data-prototype=ExpendableNonVolatile_Ram_Core0/NeTAIB_Cnt_Fan2CntrlModPerf_MFOP}, read-nv-data=NeTAIB_Cnt_Fan2CntrlModPerf_MFOP.NeTAIB_Cnt_Fan2CntrlModPerf_MFOP}
        {nv-ram-block-element=autosar-variable-in-impl-datatype={root-variable-data-prototype=ExpendableNonVolatile_RamBlock_Core0, target-data-prototype=ExpendableNonVolatile_Ram_Core0/NeTAIB_Cnt_Fan2CntrlModPerf_MFOP}, written-nv-data=NeTAIB_Cnt_Fan2CntrlModPerf_MFOP_Rx.NeTAIB_Cnt_Fan2CntrlModPerf_MFOP}
        {nv-ram-block-element=autosar-variable-in-impl-datatype={root-variable-data-prototype=ExpendableNonVolatile_RamBlock_Core0, target-data-prototype=ExpendableNonVolatile_Ram_Core0/NeTRIB_Cnt_HXCTOSSTG_MFOP}, read-nv-data=NeTRIB_Cnt_HXCTOSSTG_MFOP.NeTRIB_Cnt_HXCTOSSTG_MFOP}
        {nv-ram-block-element=autosar-variable-in-impl-datatype={root-variable-data-prototype=ExpendableNonVolatile_RamBlock_Core0, target-data-prototype=ExpendableNonVolatile_Ram_Core0/NeTRIB_Cnt_HXCTOSSTG_MFOP}, written-nv-data=NeTRIB_Cnt_HXCTOSSTG_MFOP_Rx.NeTRIB_Cnt_HXCTOSSTG_MFOP}
        {nv-ram-block-element=autosar-variable-in-impl-datatype={root-variable-data-prototype=ExpendableNonVolatile_RamBlock_Core0, target-data-prototype=ExpendableNonVolatile_Ram_Core0/NeTAIB_Cnt_OEXVInTSnsrSTB_MFOP}, read-nv-data=NeTAIB_Cnt_OEXVInTSnsrSTB_MFOP.NeTAIB_Cnt_OEXVInTSnsrSTB_MFOP}
        {nv-ram-block-element=autosar-variable-in-impl-datatype={root-variable-data-prototype=ExpendableNonVolatile_RamBlock_Core0, target-data-prototype=ExpendableNonVolatile_Ram_Core0/NeTAIB_Cnt_OEXVInTSnsrSTB_MFOP}, written-nv-data=NeTAIB_Cnt_OEXVInTSnsrSTB_MFOP_Rx.NeTAIB_Cnt_OEXVInTSnsrSTB_MFOP}
        {nv-ram-block-element=autosar-variable-in-impl-datatype={root-variable-data-prototype=ExpendableNonVolatile_RamBlock_Core0, target-data-prototype=ExpendableNonVolatile_Ram_Core0/NeTAIB_Cnt_HghRfrgtPSnsrSTG_MFOP}, read-nv-data=NeTAIB_Cnt_HghRfrgtPSnsrSTG_MFOP.NeTAIB_Cnt_HghRfrgtPSnsrSTG_MFOP}
        {nv-ram-block-element=autosar-variable-in-impl-datatype={root-variable-data-prototype=ExpendableNonVolatile_RamBlock_Core0, target-data-prototype=ExpendableNonVolatile_Ram_Core0/NeTAIB_Cnt_HghRfrgtPSnsrSTG_MFOP}, written-nv-data=NeTAIB_Cnt_HghRfrgtPSnsrSTG_MFOP_Rx.NeTAIB_Cnt_HghRfrgtPSnsrSTG_MFOP}
        {nv-ram-block-element=autosar-variable-in-impl-datatype={root-variable-data-prototype=ExpendableNonVolatile_RamBlock_Core0, target-data-prototype=ExpendableNonVolatile_Ram_Core0/NeTAIB_Cnt_HghRfrgtPSnsrSTB_MFOP}, read-nv-data=NeTAIB_Cnt_HghRfrgtPSnsrSTB_MFOP.NeTAIB_Cnt_HghRfrgtPSnsrSTB_MFOP}
        {nv-ram-block-element=autosar-variable-in-impl-datatype={root-variable-data-prototype=ExpendableNonVolatile_RamBlock_Core0, target-data-prototype=ExpendableNonVolatile_Ram_Core0/NeTAIB_Cnt_HghRfrgtPSnsrSTB_MFOP}, written-nv-data=NeTAIB_Cnt_HghRfrgtPSnsrSTB_MFOP_Rx.NeTAIB_Cnt_HghRfrgtPSnsrSTB_MFOP}
        {nv-ram-block-element=autosar-variable-in-impl-datatype={root-variable-data-prototype=ExpendableNonVolatile_RamBlock_Core0, target-data-prototype=ExpendableNonVolatile_Ram_Core0/NeTAIB_Cnt_Fan2UnderSpeed_MFOP}, read-nv-data=NeTAIB_Cnt_Fan2UnderSpeed_MFOP.NeTAIB_Cnt_Fan2UnderSpeed_MFOP}
        {nv-ram-block-element=autosar-variable-in-impl-datatype={root-variable-data-prototype=ExpendableNonVolatile_RamBlock_Core0, target-data-prototype=ExpendableNonVolatile_Ram_Core0/NeTAIB_Cnt_Fan2UnderSpeed_MFOP}, written-nv-data=NeTAIB_Cnt_Fan2UnderSpeed_MFOP_Rx.NeTAIB_Cnt_Fan2UnderSpeed_MFOP}
        {nv-ram-block-element=autosar-variable-in-impl-datatype={root-variable-data-prototype=ExpendableNonVolatile_RamBlock_Core0, target-data-prototype=ExpendableNonVolatile_Ram_Core0/NeTAIB_Cnt_Fan2StuckOff_MFOP}, read-nv-data=NeTAIB_Cnt_Fan2StuckOff_MFOP.NeTAIB_Cnt_Fan2StuckOff_MFOP}
        {nv-ram-block-element=autosar-variable-in-impl-datatype={root-variable-data-prototype=ExpendableNonVolatile_RamBlock_Core0, target-data-prototype=ExpendableNonVolatile_Ram_Core0/NeTAIB_Cnt_Fan2StuckOff_MFOP}, written-nv-data=NeTAIB_Cnt_Fan2StuckOff_MFOP_Rx.NeTAIB_Cnt_Fan2StuckOff_MFOP}
        {nv-ram-block-element=autosar-variable-in-impl-datatype={root-variable-data-prototype=ExpendableNonVolatile_RamBlock_Core0, target-data-prototype=ExpendableNonVolatile_Ram_Core0/NeTRIB_Cnt_HRCTOSSTG_MFOP}, read-nv-data=NeTRIB_Cnt_HRCTOSSTG_MFOP.NeTRIB_Cnt_HRCTOSSTG_MFOP}
        {nv-ram-block-element=autosar-variable-in-impl-datatype={root-variable-data-prototype=ExpendableNonVolatile_RamBlock_Core0, target-data-prototype=ExpendableNonVolatile_Ram_Core0/NeTRIB_Cnt_HRCTOSSTG_MFOP}, written-nv-data=NeTRIB_Cnt_HRCTOSSTG_MFOP_Rx.NeTRIB_Cnt_HRCTOSSTG_MFOP}
        {nv-ram-block-element=autosar-variable-in-impl-datatype={root-variable-data-prototype=ExpendableNonVolatile_RamBlock_Core0, target-data-prototype=ExpendableNonVolatile_Ram_Core0/NeTRIB_Cnt_HXCTOSSTB_MFOP}, read-nv-data=NeTRIB_Cnt_HXCTOSSTB_MFOP.NeTRIB_Cnt_HXCTOSSTB_MFOP}
        {nv-ram-block-element=autosar-variable-in-impl-datatype={root-variable-data-prototype=ExpendableNonVolatile_RamBlock_Core0, target-data-prototype=ExpendableNonVolatile_Ram_Core0/NeTRIB_Cnt_HXCTOSSTB_MFOP}, written-nv-data=NeTRIB_Cnt_HXCTOSSTB_MFOP_Rx.NeTRIB_Cnt_HXCTOSSTB_MFOP}
        {nv-ram-block-element=autosar-variable-in-impl-datatype={root-variable-data-prototype=ExpendableNonVolatile_RamBlock_Core0, target-data-prototype=ExpendableNonVolatile_Ram_Core0/NeTRIB_Cnt_HRCTOSSTB_MFOP}, read-nv-data=NeTRIB_Cnt_HRCTOSSTB_MFOP.NeTRIB_Cnt_HRCTOSSTB_MFOP}
        {nv-ram-block-element=autosar-variable-in-impl-datatype={root-variable-data-prototype=ExpendableNonVolatile_RamBlock_Core0, target-data-prototype=ExpendableNonVolatile_Ram_Core0/NeTRIB_Cnt_HRCTOSSTB_MFOP}, written-nv-data=NeTRIB_Cnt_HRCTOSSTB_MFOP_Rx.NeTRIB_Cnt_HRCTOSSTB_MFOP}
        {nv-ram-block-element=autosar-variable-in-impl-datatype={root-variable-data-prototype=ExpendableNonVolatile_RamBlock_Core0, target-data-prototype=ExpendableNonVolatile_Ram_Core0/NeTRIB_Cnt_HRCTISSTG_MFOP}, read-nv-data=NeTRIB_Cnt_HRCTISSTG_MFOP.NeTRIB_Cnt_HRCTISSTG_MFOP}
        {nv-ram-block-element=autosar-variable-in-impl-datatype={root-variable-data-prototype=ExpendableNonVolatile_RamBlock_Core0, target-data-prototype=ExpendableNonVolatile_Ram_Core0/NeTRIB_Cnt_HRCTISSTG_MFOP}, written-nv-data=NeTRIB_Cnt_HRCTISSTG_MFOP_Rx.NeTRIB_Cnt_HRCTISSTG_MFOP}
        {nv-ram-block-element=autosar-variable-in-impl-datatype={root-variable-data-prototype=ExpendableNonVolatile_RamBlock_Core0, target-data-prototype=ExpendableNonVolatile_Ram_Core0/NeTAIB_Cnt_RadFanErrM2_MFOP}, read-nv-data=NeTAIB_Cnt_RadFanErrM2_MFOP.NeTAIB_Cnt_RadFanErrM2_MFOP}
        {nv-ram-block-element=autosar-variable-in-impl-datatype={root-variable-data-prototype=ExpendableNonVolatile_RamBlock_Core0, target-data-prototype=ExpendableNonVolatile_Ram_Core0/NeTAIB_Cnt_RadFanErrM2_MFOP}, written-nv-data=NeTAIB_Cnt_RadFanErrM2_MFOP_Rx.NeTAIB_Cnt_RadFanErrM2_MFOP}
        {nv-ram-block-element=autosar-variable-in-impl-datatype={root-variable-data-prototype=ExpendableNonVolatile_RamBlock_Core0, target-data-prototype=ExpendableNonVolatile_Ram_Core0/NeTAIB_Cnt_RadFanErrM1_MFOP}, read-nv-data=NeTAIB_Cnt_RadFanErrM1_MFOP.NeTAIB_Cnt_RadFanErrM1_MFOP}
        {nv-ram-block-element=autosar-variable-in-impl-datatype={root-variable-data-prototype=ExpendableNonVolatile_RamBlock_Core0, target-data-prototype=ExpendableNonVolatile_Ram_Core0/NeTAIB_Cnt_RadFanErrM1_MFOP}, written-nv-data=NeTAIB_Cnt_RadFanErrM1_MFOP_Rx.NeTAIB_Cnt_RadFanErrM1_MFOP}
        {nv-ram-block-element=autosar-variable-in-impl-datatype={root-variable-data-prototype=ExpendableNonVolatile_RamBlock_Core0, target-data-prototype=ExpendableNonVolatile_Ram_Core0/NeTAIB_Cnt_RadFanErrM0_MFOP}, read-nv-data=NeTAIB_Cnt_RadFanErrM0_MFOP.NeTAIB_Cnt_RadFanErrM0_MFOP}
        {nv-ram-block-element=autosar-variable-in-impl-datatype={root-variable-data-prototype=ExpendableNonVolatile_RamBlock_Core0, target-data-prototype=ExpendableNonVolatile_Ram_Core0/NeTAIB_Cnt_RadFanErrM0_MFOP}, written-nv-data=NeTAIB_Cnt_RadFanErrM0_MFOP_Rx.NeTAIB_Cnt_RadFanErrM0_MFOP}
        {nv-ram-block-element=autosar-variable-in-impl-datatype={root-variable-data-prototype=ExpendableNonVolatile_RamBlock_Core0, target-data-prototype=ExpendableNonVolatile_Ram_Core0/NeTRIB_Cnt_HRCTISSTB_MFOP}, read-nv-data=NeTRIB_Cnt_HRCTISSTB_MFOP.NeTRIB_Cnt_HRCTISSTB_MFOP}
        {nv-ram-block-element=autosar-variable-in-impl-datatype={root-variable-data-prototype=ExpendableNonVolatile_RamBlock_Core0, target-data-prototype=ExpendableNonVolatile_Ram_Core0/NeTRIB_Cnt_HRCTISSTB_MFOP}, written-nv-data=NeTRIB_Cnt_HRCTISSTB_MFOP_Rx.NeTRIB_Cnt_HRCTISSTB_MFOP}
        {nv-ram-block-element=autosar-variable-in-impl-datatype={root-variable-data-prototype=ExpendableNonVolatile_RamBlock_Core0, target-data-prototype=ExpendableNonVolatile_Ram_Core0/NeTAIB_Cnt_OEXVInTSnsrSTG_MFOP}, read-nv-data=NeTAIB_Cnt_OEXVInTSnsrSTG_MFOP.NeTAIB_Cnt_OEXVInTSnsrSTG_MFOP}
        {nv-ram-block-element=autosar-variable-in-impl-datatype={root-variable-data-prototype=ExpendableNonVolatile_RamBlock_Core0, target-data-prototype=ExpendableNonVolatile_Ram_Core0/NeTAIB_Cnt_OEXVInTSnsrSTG_MFOP}, written-nv-data=NeTAIB_Cnt_OEXVInTSnsrSTG_MFOP_Rx.NeTAIB_Cnt_OEXVInTSnsrSTG_MFOP}
        {nv-ram-block-element=autosar-variable-in-impl-datatype={root-variable-data-prototype=ExpendableNonVolatile_RamBlock_Core0, target-data-prototype=ExpendableNonVolatile_Ram_Core0/NeTAIB_Cnt_5VAux1_MFOP}, read-nv-data=NeTAIB_Cnt_5VAux1_MFOP.NeTAIB_Cnt_5VAux1_MFOP}
        {nv-ram-block-element=autosar-variable-in-impl-datatype={root-variable-data-prototype=ExpendableNonVolatile_RamBlock_Core0, target-data-prototype=ExpendableNonVolatile_Ram_Core0/NeTAIB_Cnt_5VAux1_MFOP}, written-nv-data=NeTAIB_Cnt_5VAux1_MFOP_Rx.NeTAIB_Cnt_5VAux1_MFOP}
        {nv-ram-block-element=autosar-variable-in-impl-datatype={root-variable-data-prototype=ExpendableNonVolatile_RamBlock_Core0, target-data-prototype=ExpendableNonVolatile_Ram_Core0/NePMDB_Cnt_BpcmWakeupSTG_MFOP}, read-nv-data=NePMDB_Cnt_BpcmWakeupSTG_MFOP.NePMDB_Cnt_BpcmWakeupSTG_MFOP}
        {nv-ram-block-element=autosar-variable-in-impl-datatype={root-variable-data-prototype=ExpendableNonVolatile_RamBlock_Core0, target-data-prototype=ExpendableNonVolatile_Ram_Core0/NePMDB_Cnt_BpcmWakeupSTG_MFOP}, written-nv-data=NePMDB_Cnt_BpcmWakeupSTG_MFOP_Rx.NePMDB_Cnt_BpcmWakeupSTG_MFOP}
        {nv-ram-block-element=autosar-variable-in-impl-datatype={root-variable-data-prototype=ExpendableNonVolatile_RamBlock_Core0, target-data-prototype=ExpendableNonVolatile_Ram_Core0/NePMDB_Cnt_BpcmWakeupSTB_MFOP}, read-nv-data=NePMDB_Cnt_BpcmWakeupSTB_MFOP.NePMDB_Cnt_BpcmWakeupSTB_MFOP}
        {nv-ram-block-element=autosar-variable-in-impl-datatype={root-variable-data-prototype=ExpendableNonVolatile_RamBlock_Core0, target-data-prototype=ExpendableNonVolatile_Ram_Core0/NePMDB_Cnt_BpcmWakeupSTB_MFOP}, written-nv-data=NePMDB_Cnt_BpcmWakeupSTB_MFOP_Rx.NePMDB_Cnt_BpcmWakeupSTB_MFOP}
        {nv-ram-block-element=autosar-variable-in-impl-datatype={root-variable-data-prototype=ExpendableNonVolatile_RamBlock_Core0, target-data-prototype=ExpendableNonVolatile_Ram_Core0/NePMIB_Cnt_EleclOilPmpSpdFb_MFOP}, read-nv-data=NePMIB_Cnt_EleclOilPmpSpdFb_MFOP.NePMIB_Cnt_EleclOilPmpSpdFb_MFOP}
        {nv-ram-block-element=autosar-variable-in-impl-datatype={root-variable-data-prototype=ExpendableNonVolatile_RamBlock_Core0, target-data-prototype=ExpendableNonVolatile_Ram_Core0/NePMIB_Cnt_EleclOilPmpSpdFb_MFOP}, written-nv-data=NePMIB_Cnt_EleclOilPmpSpdFb_MFOP_Rx.NePMIB_Cnt_EleclOilPmpSpdFb_MFOP}
        {nv-ram-block-element=autosar-variable-in-impl-datatype={root-variable-data-prototype=ExpendableNonVolatile_RamBlock_Core0, target-data-prototype=ExpendableNonVolatile_Ram_Core0/NeTMIB_Cnt_PPCTISSTG_MFOP}, read-nv-data=NeTMIB_Cnt_PPCTISSTG_MFOP.NeTMIB_Cnt_PPCTISSTG_MFOP}
        {nv-ram-block-element=autosar-variable-in-impl-datatype={root-variable-data-prototype=ExpendableNonVolatile_RamBlock_Core0, target-data-prototype=ExpendableNonVolatile_Ram_Core0/NeTMIB_Cnt_PPCTISSTG_MFOP}, written-nv-data=NeTMIB_Cnt_PPCTISSTG_MFOP_Rx.NeTMIB_Cnt_PPCTISSTG_MFOP}
        {nv-ram-block-element=autosar-variable-in-impl-datatype={root-variable-data-prototype=ExpendableNonVolatile_RamBlock_Core0, target-data-prototype=ExpendableNonVolatile_Ram_Core0/NeTMIB_Cnt_ECHTISSTG_MFOP}, read-nv-data=NeTMIB_Cnt_ECHTISSTG_MFOP.NeTMIB_Cnt_ECHTISSTG_MFOP}
        {nv-ram-block-element=autosar-variable-in-impl-datatype={root-variable-data-prototype=ExpendableNonVolatile_RamBlock_Core0, target-data-prototype=ExpendableNonVolatile_Ram_Core0/NeTMIB_Cnt_ECHTISSTG_MFOP}, written-nv-data=NeTMIB_Cnt_ECHTISSTG_MFOP_Rx.NeTMIB_Cnt_ECHTISSTG_MFOP}
        {nv-ram-block-element=autosar-variable-in-impl-datatype={root-variable-data-prototype=ExpendableNonVolatile_RamBlock_Core0, target-data-prototype=ExpendableNonVolatile_Ram_Core0/NeTMIB_Cnt_PECTOSSTB_MFOP}, read-nv-data=NeTMIB_Cnt_PECTOSSTB_MFOP.NeTMIB_Cnt_PECTOSSTB_MFOP}
        {nv-ram-block-element=autosar-variable-in-impl-datatype={root-variable-data-prototype=ExpendableNonVolatile_RamBlock_Core0, target-data-prototype=ExpendableNonVolatile_Ram_Core0/NeTMIB_Cnt_PECTOSSTB_MFOP}, written-nv-data=NeTMIB_Cnt_PECTOSSTB_MFOP_Rx.NeTMIB_Cnt_PECTOSSTB_MFOP}
        {nv-ram-block-element=autosar-variable-in-impl-datatype={root-variable-data-prototype=ExpendableNonVolatile_RamBlock_Core0, target-data-prototype=ExpendableNonVolatile_Ram_Core0/NeTMIB_Cnt_PECTOSSTG_MFOP}, read-nv-data=NeTMIB_Cnt_PECTOSSTG_MFOP.NeTMIB_Cnt_PECTOSSTG_MFOP}
        {nv-ram-block-element=autosar-variable-in-impl-datatype={root-variable-data-prototype=ExpendableNonVolatile_RamBlock_Core0, target-data-prototype=ExpendableNonVolatile_Ram_Core0/NeTMIB_Cnt_PECTOSSTG_MFOP}, written-nv-data=NeTMIB_Cnt_PECTOSSTG_MFOP_Rx.NeTMIB_Cnt_PECTOSSTG_MFOP}
        {nv-ram-block-element=autosar-variable-in-impl-datatype={root-variable-data-prototype=ExpendableNonVolatile_RamBlock_Core0, target-data-prototype=ExpendableNonVolatile_Ram_Core0/NeTMIB_Cnt_PPCTISSTB_MFOP}, read-nv-data=NeTMIB_Cnt_PPCTISSTB_MFOP.NeTMIB_Cnt_PPCTISSTB_MFOP}
        {nv-ram-block-element=autosar-variable-in-impl-datatype={root-variable-data-prototype=ExpendableNonVolatile_RamBlock_Core0, target-data-prototype=ExpendableNonVolatile_Ram_Core0/NeTMIB_Cnt_PPCTISSTB_MFOP}, written-nv-data=NeTMIB_Cnt_PPCTISSTB_MFOP_Rx.NeTMIB_Cnt_PPCTISSTB_MFOP}
        {nv-ram-block-element=autosar-variable-in-impl-datatype={root-variable-data-prototype=ExpendableNonVolatile_RamBlock_Core0, target-data-prototype=ExpendableNonVolatile_Ram_Core0/NeTMIB_Cnt_ECHTISSTB_MFOP}, read-nv-data=NeTMIB_Cnt_ECHTISSTB_MFOP.NeTMIB_Cnt_ECHTISSTB_MFOP}
        {nv-ram-block-element=autosar-variable-in-impl-datatype={root-variable-data-prototype=ExpendableNonVolatile_RamBlock_Core0, target-data-prototype=ExpendableNonVolatile_Ram_Core0/NeTMIB_Cnt_ECHTISSTB_MFOP}, written-nv-data=NeTMIB_Cnt_ECHTISSTB_MFOP_Rx.NeTMIB_Cnt_ECHTISSTB_MFOP}
        {nv-ram-block-element=autosar-variable-in-impl-datatype={root-variable-data-prototype=ExpendableNonVolatile_RamBlock_Core0, target-data-prototype=ExpendableNonVolatile_Ram_Core0/NeTRIB_Cnt_BTISSTB_MFOP}, read-nv-data=NeTRIB_Cnt_BTISSTB_MFOP.NeTRIB_Cnt_BTISSTB_MFOP}
        {nv-ram-block-element=autosar-variable-in-impl-datatype={root-variable-data-prototype=ExpendableNonVolatile_RamBlock_Core0, target-data-prototype=ExpendableNonVolatile_Ram_Core0/NeTRIB_Cnt_BTISSTB_MFOP}, written-nv-data=NeTRIB_Cnt_BTISSTB_MFOP_Rx.NeTRIB_Cnt_BTISSTB_MFOP}
        {nv-ram-block-element=autosar-variable-in-impl-datatype={root-variable-data-prototype=ExpendableNonVolatile_RamBlock_Core0, target-data-prototype=ExpendableNonVolatile_Ram_Core0/NeTRIB_Cnt_HCCTOSSTG_MFOP}, read-nv-data=NeTRIB_Cnt_HCCTOSSTG_MFOP.NeTRIB_Cnt_HCCTOSSTG_MFOP}
        {nv-ram-block-element=autosar-variable-in-impl-datatype={root-variable-data-prototype=ExpendableNonVolatile_RamBlock_Core0, target-data-prototype=ExpendableNonVolatile_Ram_Core0/NeTRIB_Cnt_HCCTOSSTG_MFOP}, written-nv-data=NeTRIB_Cnt_HCCTOSSTG_MFOP_Rx.NeTRIB_Cnt_HCCTOSSTG_MFOP}
        {nv-ram-block-element=autosar-variable-in-impl-datatype={root-variable-data-prototype=ExpendableNonVolatile_RamBlock_Core0, target-data-prototype=ExpendableNonVolatile_Ram_Core0/NeTRIB_Cnt_HCCTOSSTB_MFOP}, read-nv-data=NeTRIB_Cnt_HCCTOSSTB_MFOP.NeTRIB_Cnt_HCCTOSSTB_MFOP}
        {nv-ram-block-element=autosar-variable-in-impl-datatype={root-variable-data-prototype=ExpendableNonVolatile_RamBlock_Core0, target-data-prototype=ExpendableNonVolatile_Ram_Core0/NeTRIB_Cnt_HCCTOSSTB_MFOP}, written-nv-data=NeTRIB_Cnt_HCCTOSSTB_MFOP_Rx.NeTRIB_Cnt_HCCTOSSTB_MFOP}
        {nv-ram-block-element=autosar-variable-in-impl-datatype={root-variable-data-prototype=ExpendableNonVolatile_RamBlock_Core0, target-data-prototype=ExpendableNonVolatile_Ram_Core0/NeTRIB_Cnt_HCCTISSTG_MFOP}, read-nv-data=NeTRIB_Cnt_HCCTISSTG_MFOP.NeTRIB_Cnt_HCCTISSTG_MFOP}
        {nv-ram-block-element=autosar-variable-in-impl-datatype={root-variable-data-prototype=ExpendableNonVolatile_RamBlock_Core0, target-data-prototype=ExpendableNonVolatile_Ram_Core0/NeTRIB_Cnt_HCCTISSTG_MFOP}, written-nv-data=NeTRIB_Cnt_HCCTISSTG_MFOP_Rx.NeTRIB_Cnt_HCCTISSTG_MFOP}
        {nv-ram-block-element=autosar-variable-in-impl-datatype={root-variable-data-prototype=ExpendableNonVolatile_RamBlock_Core0, target-data-prototype=ExpendableNonVolatile_Ram_Core0/NeTRIB_Cnt_BTISSTG_MFOP}, read-nv-data=NeTRIB_Cnt_BTISSTG_MFOP.NeTRIB_Cnt_BTISSTG_MFOP}
        {nv-ram-block-element=autosar-variable-in-impl-datatype={root-variable-data-prototype=ExpendableNonVolatile_RamBlock_Core0, target-data-prototype=ExpendableNonVolatile_Ram_Core0/NeTRIB_Cnt_BTISSTG_MFOP}, written-nv-data=NeTRIB_Cnt_BTISSTG_MFOP_Rx.NeTRIB_Cnt_BTISSTG_MFOP}
        {nv-ram-block-element=autosar-variable-in-impl-datatype={root-variable-data-prototype=ExpendableNonVolatile_RamBlock_Core0, target-data-prototype=ExpendableNonVolatile_Ram_Core0/NeTRIB_Cnt_BTOSSTB_MFOP}, read-nv-data=NeTRIB_Cnt_BTOSSTB_MFOP.NeTRIB_Cnt_BTOSSTB_MFOP}
        {nv-ram-block-element=autosar-variable-in-impl-datatype={root-variable-data-prototype=ExpendableNonVolatile_RamBlock_Core0, target-data-prototype=ExpendableNonVolatile_Ram_Core0/NeTRIB_Cnt_BTOSSTB_MFOP}, written-nv-data=NeTRIB_Cnt_BTOSSTB_MFOP_Rx.NeTRIB_Cnt_BTOSSTB_MFOP}
        {nv-ram-block-element=autosar-variable-in-impl-datatype={root-variable-data-prototype=ExpendableNonVolatile_RamBlock_Core0, target-data-prototype=ExpendableNonVolatile_Ram_Core0/NeTRIB_Cnt_HCCTISSTB_MFOP}, read-nv-data=NeTRIB_Cnt_HCCTISSTB_MFOP.NeTRIB_Cnt_HCCTISSTB_MFOP}
        {nv-ram-block-element=autosar-variable-in-impl-datatype={root-variable-data-prototype=ExpendableNonVolatile_RamBlock_Core0, target-data-prototype=ExpendableNonVolatile_Ram_Core0/NeTRIB_Cnt_HCCTISSTB_MFOP}, written-nv-data=NeTRIB_Cnt_HCCTISSTB_MFOP_Rx.NeTRIB_Cnt_HCCTISSTB_MFOP}
        {nv-ram-block-element=autosar-variable-in-impl-datatype={root-variable-data-prototype=ExpendableNonVolatile_RamBlock_Core0, target-data-prototype=ExpendableNonVolatile_Ram_Core0/NeTRIB_Cnt_BTOSSTG_MFOP}, read-nv-data=NeTRIB_Cnt_BTOSSTG_MFOP.NeTRIB_Cnt_BTOSSTG_MFOP}
        {nv-ram-block-element=autosar-variable-in-impl-datatype={root-variable-data-prototype=ExpendableNonVolatile_RamBlock_Core0, target-data-prototype=ExpendableNonVolatile_Ram_Core0/NeTRIB_Cnt_BTOSSTG_MFOP}, written-nv-data=NeTRIB_Cnt_BTOSSTG_MFOP_Rx.NeTRIB_Cnt_BTOSSTG_MFOP}
        {nv-ram-block-element=autosar-variable-in-impl-datatype={root-variable-data-prototype=ExpendableNonVolatile_RamBlock_Core0, target-data-prototype=ExpendableNonVolatile_Ram_Core0/NeTRIB_Cnt_BatClntSnsSTG_MFOP}, read-nv-data=NeTRIB_Cnt_BatClntSnsSTG_MFOP.NeTRIB_Cnt_BatClntSnsSTG_MFOP}
        {nv-ram-block-element=autosar-variable-in-impl-datatype={root-variable-data-prototype=ExpendableNonVolatile_RamBlock_Core0, target-data-prototype=ExpendableNonVolatile_Ram_Core0/NeTRIB_Cnt_BatClntSnsSTG_MFOP}, written-nv-data=NeTRIB_Cnt_BatClntSnsSTG_MFOP_Rx.NeTRIB_Cnt_BatClntSnsSTG_MFOP}
        {nv-ram-block-element=autosar-variable-in-impl-datatype={root-variable-data-prototype=ExpendableNonVolatile_RamBlock_Core0, target-data-prototype=ExpendableNonVolatile_Ram_Core0/NeDMIB_Cnt_PadLvrSTG_MFOP}, read-nv-data=NeDMIB_Cnt_PadLvrSTG_MFOP.NeDMIB_Cnt_PadLvrSTG_MFOP}
        {nv-ram-block-element=autosar-variable-in-impl-datatype={root-variable-data-prototype=ExpendableNonVolatile_RamBlock_Core0, target-data-prototype=ExpendableNonVolatile_Ram_Core0/NeDMIB_Cnt_PadLvrSTG_MFOP}, written-nv-data=NeDMIB_Cnt_PadLvrSTG_MFOP_Rx.NeDMIB_Cnt_PadLvrSTG_MFOP}
        {nv-ram-block-element=autosar-variable-in-impl-datatype={root-variable-data-prototype=ExpendableNonVolatile_RamBlock_Core0, target-data-prototype=ExpendableNonVolatile_Ram_Core0/NeDMIB_Cnt_PadLvrSTB_MFOP}, read-nv-data=NeDMIB_Cnt_PadLvrSTB_MFOP.NeDMIB_Cnt_PadLvrSTB_MFOP}
        {nv-ram-block-element=autosar-variable-in-impl-datatype={root-variable-data-prototype=ExpendableNonVolatile_RamBlock_Core0, target-data-prototype=ExpendableNonVolatile_Ram_Core0/NeDMIB_Cnt_PadLvrSTB_MFOP}, written-nv-data=NeDMIB_Cnt_PadLvrSTB_MFOP_Rx.NeDMIB_Cnt_PadLvrSTB_MFOP}
        {nv-ram-block-element=autosar-variable-in-impl-datatype={root-variable-data-prototype=ExpendableNonVolatile_RamBlock_Core0, target-data-prototype=ExpendableNonVolatile_Ram_Core0/NeADFB_Cnt_A2DFault_MFOP}, read-nv-data=NeADFB_Cnt_A2DFault_MFOP.NeADFB_Cnt_A2DFault_MFOP}
        {nv-ram-block-element=autosar-variable-in-impl-datatype={root-variable-data-prototype=ExpendableNonVolatile_RamBlock_Core0, target-data-prototype=ExpendableNonVolatile_Ram_Core0/NeADFB_Cnt_A2DFault_MFOP}, written-nv-data=NeADFB_Cnt_A2DFault_MFOP_Rx.NeADFB_Cnt_A2DFault_MFOP}
        {nv-ram-block-element=autosar-variable-in-impl-datatype={root-variable-data-prototype=ExpendableNonVolatile_RamBlock_Core0, target-data-prototype=ExpendableNonVolatile_Ram_Core0/NeNVMB_Cnt_RadFan2CtrlSTG_MFOP}, read-nv-data=NeNVMB_Cnt_RadFan2CtrlSTG_MFOP.NeNVMB_Cnt_RadFan2CtrlSTG_MFOP}
        {nv-ram-block-element=autosar-variable-in-impl-datatype={root-variable-data-prototype=ExpendableNonVolatile_RamBlock_Core0, target-data-prototype=ExpendableNonVolatile_Ram_Core0/NeNVMB_Cnt_RadFan2CtrlSTG_MFOP}, written-nv-data=NeNVMB_Cnt_RadFan2CtrlSTG_MFOP_Rx.NeNVMB_Cnt_RadFan2CtrlSTG_MFOP}
        {nv-ram-block-element=autosar-variable-in-impl-datatype={root-variable-data-prototype=ExpendableNonVolatile_RamBlock_Core0, target-data-prototype=ExpendableNonVolatile_Ram_Core0/NeNVMB_Cnt_STGFtRfgtShtOffVlv_MFOP}, read-nv-data=NeNVMB_Cnt_STGFtRfgtShtOffVlv_MFOP.NeNVMB_Cnt_STGFtRfgtShtOffVlv_MFOP}
        {nv-ram-block-element=autosar-variable-in-impl-datatype={root-variable-data-prototype=ExpendableNonVolatile_RamBlock_Core0, target-data-prototype=ExpendableNonVolatile_Ram_Core0/NeNVMB_Cnt_STGFtRfgtShtOffVlv_MFOP}, written-nv-data=NeNVMB_Cnt_STGFtRfgtShtOffVlv_MFOP_Rx.NeNVMB_Cnt_STGFtRfgtShtOffVlv_MFOP}
        {nv-ram-block-element=autosar-variable-in-impl-datatype={root-variable-data-prototype=ExpendableNonVolatile_RamBlock_Core0, target-data-prototype=ExpendableNonVolatile_Ram_Core0/NeNVMB_Cnt_STBFtRfgtShtOffVlv_MFOP}, read-nv-data=NeNVMB_Cnt_STBFtRfgtShtOffVlv_MFOP.NeNVMB_Cnt_STBFtRfgtShtOffVlv_MFOP}
        {nv-ram-block-element=autosar-variable-in-impl-datatype={root-variable-data-prototype=ExpendableNonVolatile_RamBlock_Core0, target-data-prototype=ExpendableNonVolatile_Ram_Core0/NeNVMB_Cnt_STBFtRfgtShtOffVlv_MFOP}, written-nv-data=NeNVMB_Cnt_STBFtRfgtShtOffVlv_MFOP_Rx.NeNVMB_Cnt_STBFtRfgtShtOffVlv_MFOP}
        {nv-ram-block-element=autosar-variable-in-impl-datatype={root-variable-data-prototype=ExpendableNonVolatile_RamBlock_Core0, target-data-prototype=ExpendableNonVolatile_Ram_Core0/NeNVMB_Cnt_RadrFanCtrlSTG_MFOP}, read-nv-data=NeNVMB_Cnt_RadrFanCtrlSTG_MFOP.NeNVMB_Cnt_RadrFanCtrlSTG_MFOP}
        {nv-ram-block-element=autosar-variable-in-impl-datatype={root-variable-data-prototype=ExpendableNonVolatile_RamBlock_Core0, target-data-prototype=ExpendableNonVolatile_Ram_Core0/NeNVMB_Cnt_RadrFanCtrlSTG_MFOP}, written-nv-data=NeNVMB_Cnt_RadrFanCtrlSTG_MFOP_Rx.NeNVMB_Cnt_RadrFanCtrlSTG_MFOP}
        {nv-ram-block-element=autosar-variable-in-impl-datatype={root-variable-data-prototype=ExpendableNonVolatile_RamBlock_Core0, target-data-prototype=ExpendableNonVolatile_Ram_Core0/NeNVMB_Cnt_RadrFanCtrlSTB_MFOP}, read-nv-data=NeNVMB_Cnt_RadrFanCtrlSTB_MFOP.NeNVMB_Cnt_RadrFanCtrlSTB_MFOP}
        {nv-ram-block-element=autosar-variable-in-impl-datatype={root-variable-data-prototype=ExpendableNonVolatile_RamBlock_Core0, target-data-prototype=ExpendableNonVolatile_Ram_Core0/NeNVMB_Cnt_RadrFanCtrlSTB_MFOP}, written-nv-data=NeNVMB_Cnt_RadrFanCtrlSTB_MFOP_Rx.NeNVMB_Cnt_RadrFanCtrlSTB_MFOP}
        {nv-ram-block-element=autosar-variable-in-impl-datatype={root-variable-data-prototype=ExpendableNonVolatile_RamBlock_Core0, target-data-prototype=ExpendableNonVolatile_Ram_Core0/NeNVMB_Cnt_RadFan2CtrlSTB_MFOP}, read-nv-data=NeNVMB_Cnt_RadFan2CtrlSTB_MFOP.NeNVMB_Cnt_RadFan2CtrlSTB_MFOP}
        {nv-ram-block-element=autosar-variable-in-impl-datatype={root-variable-data-prototype=ExpendableNonVolatile_RamBlock_Core0, target-data-prototype=ExpendableNonVolatile_Ram_Core0/NeNVMB_Cnt_RadFan2CtrlSTB_MFOP}, written-nv-data=NeNVMB_Cnt_RadFan2CtrlSTB_MFOP_Rx.NeNVMB_Cnt_RadFan2CtrlSTB_MFOP}
        {nv-ram-block-element=autosar-variable-in-impl-datatype={root-variable-data-prototype=ExpendableNonVolatile_RamBlock_Core0, target-data-prototype=ExpendableNonVolatile_Ram_Core0/NeNVMB_Cnt_RadFan2CtrlOC_MFOP}, read-nv-data=NeNVMB_Cnt_RadFan2CtrlOC_MFOP.NeNVMB_Cnt_RadFan2CtrlOC_MFOP}
        {nv-ram-block-element=autosar-variable-in-impl-datatype={root-variable-data-prototype=ExpendableNonVolatile_RamBlock_Core0, target-data-prototype=ExpendableNonVolatile_Ram_Core0/NeNVMB_Cnt_RadFan2CtrlOC_MFOP}, written-nv-data=NeNVMB_Cnt_RadFan2CtrlOC_MFOP_Rx.NeNVMB_Cnt_RadFan2CtrlOC_MFOP}
        {nv-ram-block-element=autosar-variable-in-impl-datatype={root-variable-data-prototype=ExpendableNonVolatile_RamBlock_Core0, target-data-prototype=ExpendableNonVolatile_Ram_Core0/NeNVMB_Cnt_ePTWakeUpEnblOC_MFOP}, read-nv-data=NeNVMB_Cnt_ePTWakeUpEnblOC_MFOP.NeNVMB_Cnt_ePTWakeUpEnblOC_MFOP}
        {nv-ram-block-element=autosar-variable-in-impl-datatype={root-variable-data-prototype=ExpendableNonVolatile_RamBlock_Core0, target-data-prototype=ExpendableNonVolatile_Ram_Core0/NeNVMB_Cnt_ePTWakeUpEnblOC_MFOP}, written-nv-data=NeNVMB_Cnt_ePTWakeUpEnblOC_MFOP_Rx.NeNVMB_Cnt_ePTWakeUpEnblOC_MFOP}
        {nv-ram-block-element=autosar-variable-in-impl-datatype={root-variable-data-prototype=ExpendableNonVolatile_RamBlock_Core0, target-data-prototype=ExpendableNonVolatile_Ram_Core0/NeNVMB_Cnt_ePTWakeUpEnblSTB_MFOP}, read-nv-data=NeNVMB_Cnt_ePTWakeUpEnblSTB_MFOP.NeNVMB_Cnt_ePTWakeUpEnblSTB_MFOP}
        {nv-ram-block-element=autosar-variable-in-impl-datatype={root-variable-data-prototype=ExpendableNonVolatile_RamBlock_Core0, target-data-prototype=ExpendableNonVolatile_Ram_Core0/NeNVMB_Cnt_ePTWakeUpEnblSTB_MFOP}, written-nv-data=NeNVMB_Cnt_ePTWakeUpEnblSTB_MFOP_Rx.NeNVMB_Cnt_ePTWakeUpEnblSTB_MFOP}
        {nv-ram-block-element=autosar-variable-in-impl-datatype={root-variable-data-prototype=ExpendableNonVolatile_RamBlock_Core0, target-data-prototype=ExpendableNonVolatile_Ram_Core0/NeNVMB_Cnt_ePTWakeUpEnblSTG_MFOP}, read-nv-data=NeNVMB_Cnt_ePTWakeUpEnblSTG_MFOP.NeNVMB_Cnt_ePTWakeUpEnblSTG_MFOP}
        {nv-ram-block-element=autosar-variable-in-impl-datatype={root-variable-data-prototype=ExpendableNonVolatile_RamBlock_Core0, target-data-prototype=ExpendableNonVolatile_Ram_Core0/NeNVMB_Cnt_ePTWakeUpEnblSTG_MFOP}, written-nv-data=NeNVMB_Cnt_ePTWakeUpEnblSTG_MFOP_Rx.NeNVMB_Cnt_ePTWakeUpEnblSTG_MFOP}
        {nv-ram-block-element=autosar-variable-in-impl-datatype={root-variable-data-prototype=ExpendableNonVolatile_RamBlock_Core0, target-data-prototype=ExpendableNonVolatile_Ram_Core0/NeNVMB_Cnt_FtRfgtShtOffVlvOC_MFOP}, read-nv-data=NeNVMB_Cnt_FtRfgtShtOffVlvOC_MFOP.NeNVMB_Cnt_FtRfgtShtOffVlvOC_MFOP}
        {nv-ram-block-element=autosar-variable-in-impl-datatype={root-variable-data-prototype=ExpendableNonVolatile_RamBlock_Core0, target-data-prototype=ExpendableNonVolatile_Ram_Core0/NeNVMB_Cnt_FtRfgtShtOffVlvOC_MFOP}, written-nv-data=NeNVMB_Cnt_FtRfgtShtOffVlvOC_MFOP_Rx.NeNVMB_Cnt_FtRfgtShtOffVlvOC_MFOP}
        {nv-ram-block-element=autosar-variable-in-impl-datatype={root-variable-data-prototype=ExpendableNonVolatile_RamBlock_Core0, target-data-prototype=ExpendableNonVolatile_Ram_Core0/NeNVMB_Cnt_ThermSysEnbl_MFOP}, read-nv-data=NeNVMB_Cnt_ThermSysEnbl_MFOP.NeNVMB_Cnt_ThermSysEnbl_MFOP}
        {nv-ram-block-element=autosar-variable-in-impl-datatype={root-variable-data-prototype=ExpendableNonVolatile_RamBlock_Core0, target-data-prototype=ExpendableNonVolatile_Ram_Core0/NeNVMB_Cnt_ThermSysEnbl_MFOP}, written-nv-data=NeNVMB_Cnt_ThermSysEnbl_MFOP_Rx.NeNVMB_Cnt_ThermSysEnbl_MFOP}
        {nv-ram-block-element=autosar-variable-in-impl-datatype={root-variable-data-prototype=ExpendableNonVolatile_RamBlock_Core0, target-data-prototype=ExpendableNonVolatile_Ram_Core0/NeNVMB_Cnt_RadrFanCtrlOC_MFOP}, read-nv-data=NeNVMB_Cnt_RadrFanCtrlOC_MFOP.NeNVMB_Cnt_RadrFanCtrlOC_MFOP}
        {nv-ram-block-element=autosar-variable-in-impl-datatype={root-variable-data-prototype=ExpendableNonVolatile_RamBlock_Core0, target-data-prototype=ExpendableNonVolatile_Ram_Core0/NeNVMB_Cnt_RadrFanCtrlOC_MFOP}, written-nv-data=NeNVMB_Cnt_RadrFanCtrlOC_MFOP_Rx.NeNVMB_Cnt_RadrFanCtrlOC_MFOP}
        {nv-ram-block-element=autosar-variable-in-impl-datatype={root-variable-data-prototype=ExpendableNonVolatile_RamBlock_Core0, target-data-prototype=ExpendableNonVolatile_Ram_Core0/NeBSWR_e_ShutOffPathTestStatus_prev}, read-nv-data=NeBSWR_e_ShutOffPathTestStatus_prev.NeBSWR_e_ShutOffPathTestStatus_prev}
        {nv-ram-block-element=autosar-variable-in-impl-datatype={root-variable-data-prototype=ExpendableNonVolatile_RamBlock_Core0, target-data-prototype=ExpendableNonVolatile_Ram_Core0/NeBSWR_e_ShutOffPathTestStatus_prev}, written-nv-data=NeBSWR_e_ShutOffPathTestStatus_prev_Rx.NeBSWR_e_ShutOffPathTestStatus_prev}
        {nv-ram-block-element=autosar-variable-in-impl-datatype={root-variable-data-prototype=ExpendableNonVolatile_RamBlock_Core0, target-data-prototype=ExpendableNonVolatile_Ram_Core0/NeSPT_SkippedOccurenceCounter}, read-nv-data=NeSPT_SkippedOccurenceCounter.NeSPT_SkippedOccurenceCounter}
        {nv-ram-block-element=autosar-variable-in-impl-datatype={root-variable-data-prototype=ExpendableNonVolatile_RamBlock_Core0, target-data-prototype=ExpendableNonVolatile_Ram_Core0/NeSPT_SkippedOccurenceCounter}, written-nv-data=NeSPT_SkippedOccurenceCounter_Rx.NeSPT_SkippedOccurenceCounter}
        {nv-ram-block-element=autosar-variable-in-impl-datatype={root-variable-data-prototype=ExpendableNonVolatile_RamBlock_Core0, target-data-prototype=ExpendableNonVolatile_Ram_Core0/NeSPT_AttemptsCounter}, read-nv-data=NeSPT_AttemptsCounter.NeSPT_AttemptsCounter}
        {nv-ram-block-element=autosar-variable-in-impl-datatype={root-variable-data-prototype=ExpendableNonVolatile_RamBlock_Core0, target-data-prototype=ExpendableNonVolatile_Ram_Core0/NeSPT_AttemptsCounter}, written-nv-data=NeSPT_AttemptsCounter_Rx.NeSPT_AttemptsCounter}
      nv block needs NvBlockNeeds: calc-ram-block-crc=false, check-static-block-id=false, readonly=false, resistant-to-changed-sw=false, restore-at-start=true, store-at-shutdown=true, store-cyclic=false, store-emergency=false, store-immediate=false, use-auto-validation-at-shut-down=false, use-crc-comp-mechanism=true, write-only-once=false, write-verification=false
      ram block ExpendableNonVolatile_RamBlock_Core0: type=ExpendableNonVolatile_Ram_Core0, init-value={short-label=ExpendableNonVolatile_Ram_Core0, fields=[NeAPSR_U_Lv1PvAdapt:0, NeTAIB_Cnt_Fan2CntrlModPerf_MFOP:0, NeTRIB_Cnt_HXCTOSSTG_MFOP:0, NeTAIB_Cnt_OEXVInTSnsrSTB_MFOP:0, NeTAIB_Cnt_HghRfrgtPSnsrSTG_MFOP:0, NeTAIB_Cnt_HghRfrgtPSnsrSTB_MFOP:0, NeTAIB_Cnt_Fan2UnderSpeed_MFOP:0, NeTAIB_Cnt_Fan2StuckOff_MFOP:0, NeTRIB_Cnt_HRCTOSSTG_MFOP:0, NeTRIB_Cnt_HXCTOSSTB_MFOP:0, NeTRIB_Cnt_HRCTOSSTB_MFOP:0, NeTRIB_Cnt_HRCTISSTG_MFOP:0, NeTAIB_Cnt_RadFanErrM2_MFOP:0, NeTAIB_Cnt_RadFanErrM1_MFOP:0, NeTAIB_Cnt_RadFanErrM0_MFOP:0, NeTRIB_Cnt_HRCTISSTB_MFOP:0, NeTAIB_Cnt_OEXVInTSnsrSTG_MFOP:0, NeTAIB_Cnt_5VAux1_MFOP:0, NePMDB_Cnt_BpcmWakeupSTG_MFOP:0, NePMDB_Cnt_BpcmWakeupSTB_MFOP:0, NePMIB_Cnt_EleclOilPmpSpdFb_MFOP:0, NeTMIB_Cnt_PPCTISSTG_MFOP:0, NeTMIB_Cnt_ECHTISSTG_MFOP:0, NeTMIB_Cnt_PECTOSSTB_MFOP:0, NeTMIB_Cnt_PECTOSSTG_MFOP:0, NeTMIB_Cnt_PPCTISSTB_MFOP:0, NeTMIB_Cnt_ECHTISSTB_MFOP:0, NeTRIB_Cnt_BTISSTB_MFOP:0, NeTRIB_Cnt_HCCTOSSTG_MFOP:0, NeTRIB_Cnt_HCCTOSSTB_MFOP:0, NeTRIB_Cnt_HCCTISSTG_MFOP:0, NeTRIB_Cnt_BTISSTG_MFOP:0, NeTRIB_Cnt_BTOSSTB_MFOP:0, NeTRIB_Cnt_HCCTISSTB_MFOP:0, NeTRIB_Cnt_BTOSSTG_MFOP:0, NeTRIB_Cnt_BatClntSnsSTG_MFOP:0, NeDMIB_Cnt_PadLvrSTG_MFOP:0, NeDMIB_Cnt_PadLvrSTB_MFOP:0, NeADFB_Cnt_A2DFault_MFOP:0, NeNVMB_Cnt_RadFan2CtrlSTG_MFOP:0, NeNVMB_Cnt_STGFtRfgtShtOffVlv_MFOP:0, NeNVMB_Cnt_STBFtRfgtShtOffVlv_MFOP:0, NeNVMB_Cnt_RadrFanCtrlSTG_MFOP:0, NeNVMB_Cnt_RadrFanCtrlSTB_MFOP:0, NeNVMB_Cnt_RadFan2CtrlSTB_MFOP:0, NeNVMB_Cnt_RadFan2CtrlOC_MFOP:0, NeNVMB_Cnt_ePTWakeUpEnblOC_MFOP:0, NeNVMB_Cnt_ePTWakeUpEnblSTB_MFOP:0, NeNVMB_Cnt_ePTWakeUpEnblSTG_MFOP:0, NeNVMB_Cnt_FtRfgtShtOffVlvOC_MFOP:0, NeNVMB_Cnt_ThermSysEnbl_MFOP:0, NeNVMB_Cnt_RadrFanCtrlOC_MFOP:0, NeBSWR_e_ShutOffPathTestStatus_prev:0, NeSPT_SkippedOccurenceCounter:0, NeSPT_AttemptsCounter:0, Reserved1:0, Reserved2:0, Reserved3:0, Reserved4:0, Reserved5:0, Reserved6:0, Reserved7:0, Reserved8:0, Reserved9:0, Reserved10:0, Reserved11:0, Reserved12:0, Reserved13:0, Reserved14:0, Reserved15:0, Reserved16:0, Reserved17:0, Reserved18:0, Reserved19:0, Reserved20:0, Reserved21:0, Reserved22:0, Reserved23:0, Reserved24:0, Reserved25:0, Reserved26:0, Reserved27:0]}
      rom block ExpendableNonVolatile_RomBlock_Core0: type=ExpendableNonVolatile_Rom_Core0, init-value={short-label=ExpendableNonVolatile_Rom_Core0, fields=[NeAPSR_U_Lv1PvAdapt:0, NeTAIB_Cnt_Fan2CntrlModPerf_MFOP:0, NeTRIB_Cnt_HXCTOSSTG_MFOP:0, NeTAIB_Cnt_OEXVInTSnsrSTB_MFOP:0, NeTAIB_Cnt_HghRfrgtPSnsrSTG_MFOP:0, NeTAIB_Cnt_HghRfrgtPSnsrSTB_MFOP:0, NeTAIB_Cnt_Fan2UnderSpeed_MFOP:0, NeTAIB_Cnt_Fan2StuckOff_MFOP:0, NeTRIB_Cnt_HRCTOSSTG_MFOP:0, NeTRIB_Cnt_HXCTOSSTB_MFOP:0, NeTRIB_Cnt_HRCTOSSTB_MFOP:0, NeTRIB_Cnt_HRCTISSTG_MFOP:0, NeTAIB_Cnt_RadFanErrM2_MFOP:0, NeTAIB_Cnt_RadFanErrM1_MFOP:0, NeTAIB_Cnt_RadFanErrM0_MFOP:0, NeTRIB_Cnt_HRCTISSTB_MFOP:0, NeTAIB_Cnt_OEXVInTSnsrSTG_MFOP:0, NeTAIB_Cnt_5VAux1_MFOP:0, NePMDB_Cnt_BpcmWakeupSTG_MFOP:0, NePMDB_Cnt_BpcmWakeupSTB_MFOP:0, NePMIB_Cnt_EleclOilPmpSpdFb_MFOP:0, NeTMIB_Cnt_PPCTISSTG_MFOP:0, NeTMIB_Cnt_ECHTISSTG_MFOP:0, NeTMIB_Cnt_PECTOSSTB_MFOP:0, NeTMIB_Cnt_PECTOSSTG_MFOP:0, NeTMIB_Cnt_PPCTISSTB_MFOP:0, NeTMIB_Cnt_ECHTISSTB_MFOP:0, NeTRIB_Cnt_BTISSTB_MFOP:0, NeTRIB_Cnt_HCCTOSSTG_MFOP:0, NeTRIB_Cnt_HCCTOSSTB_MFOP:0, NeTRIB_Cnt_HCCTISSTG_MFOP:0, NeTRIB_Cnt_BTISSTG_MFOP:0, NeTRIB_Cnt_BTOSSTB_MFOP:0, NeTRIB_Cnt_HCCTISSTB_MFOP:0, NeTRIB_Cnt_BTOSSTG_MFOP:0, NeTRIB_Cnt_BatClntSnsSTG_MFOP:0, NeDMIB_Cnt_PadLvrSTG_MFOP:0, NeDMIB_Cnt_PadLvrSTB_MFOP:0, NeADFB_Cnt_A2DFault_MFOP:0, NeNVMB_Cnt_RadFan2CtrlSTG_MFOP:0, NeNVMB_Cnt_STGFtRfgtShtOffVlv_MFOP:0, NeNVMB_Cnt_STBFtRfgtShtOffVlv_MFOP:0, NeNVMB_Cnt_RadrFanCtrlSTG_MFOP:0, NeNVMB_Cnt_RadrFanCtrlSTB_MFOP:0, NeNVMB_Cnt_RadFan2CtrlSTB_MFOP:0, NeNVMB_Cnt_RadFan2CtrlOC_MFOP:0, NeNVMB_Cnt_ePTWakeUpEnblOC_MFOP:0, NeNVMB_Cnt_ePTWakeUpEnblSTB_MFOP:0, NeNVMB_Cnt_ePTWakeUpEnblSTG_MFOP:0, NeNVMB_Cnt_FtRfgtShtOffVlvOC_MFOP:0, NeNVMB_Cnt_ThermSysEnbl_MFOP:0, NeNVMB_Cnt_RadrFanCtrlOC_MFOP:0, NeBSWR_e_ShutOffPathTestStatus_prev:0, NeSPT_SkippedOccurenceCounter:0, NeSPT_AttemptsCounter:0, Reserved1:0, Reserved2:0, Reserved3:0, Reserved4:0, Reserved5:0, Reserved6:0, Reserved7:0, Reserved8:0, Reserved9:0, Reserved10:0, Reserved11:0, Reserved12:0, Reserved13:0, Reserved14:0, Reserved15:0, Reserved16:0, Reserved17:0, Reserved18:0, Reserved19:0, Reserved20:0, Reserved21:0, Reserved22:0, Reserved23:0, Reserved24:0, Reserved25:0, Reserved26:0, Reserved27:0]}
    nv block descriptor EE_PEDAL_SENSOR_StrIMM_Descr_Core0: support-dirty-flag=true
      nv-block-data-mappings:
        {nv-ram-block-element=autosar-variable-in-impl-datatype={root-variable-data-prototype=EE_PEDAL_SENSOR_StrIMM_RamBlock_Core0, target-data-prototype=EE_PEDAL_SENSOR_StrIMM_Ram_Core0/AeAPSR_U_Pvs1MaxValue}, read-nv-data=AeAPSR_U_Pvs1MaxValue.AeAPSR_U_Pvs1MaxValue}
        {nv-ram-block-element=autosar-variable-in-impl-datatype={root-variable-data-prototype=EE_PEDAL_SENSOR_StrIMM_RamBlock_Core0, target-data-prototype=EE_PEDAL_SENSOR_StrIMM_Ram_Core0/AeAPSR_U_Pvs1MaxValue}, written-nv-data=AeAPSR_U_Pvs1MaxValue_Rx.AeAPSR_U_Pvs1MaxValue}
        {nv-ram-block-element=autosar-variable-in-impl-datatype={root-variable-data-prototype=EE_PEDAL_SENSOR_StrIMM_RamBlock_Core0, target-data-prototype=EE_PEDAL_SENSOR_StrIMM_Ram_Core0/AeAPSR_U_Pvs1MinValue}, read-nv-data=AeAPSR_U_Pvs1MinValue.AeAPSR_U_Pvs1MinValue}
        {nv-ram-block-element=autosar-variable-in-impl-datatype={root-variable-data-prototype=EE_PEDAL_SENSOR_StrIMM_RamBlock_Core0, target-data-prototype=EE_PEDAL_SENSOR_StrIMM_Ram_Core0/AeAPSR_U_Pvs1MinValue}, written-nv-data=AeAPSR_U_Pvs1MinValue_Rx.AeAPSR_U_Pvs1MinValue}
        {nv-ram-block-element=autosar-variable-in-impl-datatype={root-variable-data-prototype=EE_PEDAL_SENSOR_StrIMM_RamBlock_Core0, target-data-prototype=EE_PEDAL_SENSOR_StrIMM_Ram_Core0/AeAPSR_U_Pvs2MaxValue}, read-nv-data=AeAPSR_U_Pvs2MaxValue.AeAPSR_U_Pvs2MaxValue}
        {nv-ram-block-element=autosar-variable-in-impl-datatype={root-variable-data-prototype=EE_PEDAL_SENSOR_StrIMM_RamBlock_Core0, target-data-prototype=EE_PEDAL_SENSOR_StrIMM_Ram_Core0/AeAPSR_U_Pvs2MaxValue}, written-nv-data=AeAPSR_U_Pvs2MaxValue_Rx.AeAPSR_U_Pvs2MaxValue}
        {nv-ram-block-element=autosar-variable-in-impl-datatype={root-variable-data-prototype=EE_PEDAL_SENSOR_StrIMM_RamBlock_Core0, target-data-prototype=EE_PEDAL_SENSOR_StrIMM_Ram_Core0/AeAPSR_U_Pvs2MinValue}, read-nv-data=AeAPSR_U_Pvs2MinValue.AeAPSR_U_Pvs2MinValue}
        {nv-ram-block-element=autosar-variable-in-impl-datatype={root-variable-data-prototype=EE_PEDAL_SENSOR_StrIMM_RamBlock_Core0, target-data-prototype=EE_PEDAL_SENSOR_StrIMM_Ram_Core0/AeAPSR_U_Pvs2MinValue}, written-nv-data=AeAPSR_U_Pvs2MinValue_Rx.AeAPSR_U_Pvs2MinValue}
        {nv-ram-block-element=autosar-variable-in-impl-datatype={root-variable-data-prototype=EE_PEDAL_SENSOR_StrIMM_RamBlock_Core0, target-data-prototype=EE_PEDAL_SENSOR_StrIMM_Ram_Core0/AeAPSR_b_Pv2MinTestNotCmplt}, read-nv-data=AeAPSR_b_Pv2MinTestNotCmplt.AeAPSR_b_Pv2MinTestNotCmplt}
        {nv-ram-block-element=autosar-variable-in-impl-datatype={root-variable-data-prototype=EE_PEDAL_SENSOR_StrIMM_RamBlock_Core0, target-data-prototype=EE_PEDAL_SENSOR_StrIMM_Ram_Core0/AeAPSR_b_Pv2MinTestNotCmplt}, written-nv-data=AeAPSR_b_Pv2MinTestNotCmplt_Rx.AeAPSR_b_Pv2MinTestNotCmplt}
        {nv-ram-block-element=autosar-variable-in-impl-datatype={root-variable-data-prototype=EE_PEDAL_SENSOR_StrIMM_RamBlock_Core0, target-data-prototype=EE_PEDAL_SENSOR_StrIMM_Ram_Core0/AeAPSR_b_Pv2MinTestFailed}, read-nv-data=AeAPSR_b_Pv2MinTestFailed.AeAPSR_b_Pv2MinTestFailed}
        {nv-ram-block-element=autosar-variable-in-impl-datatype={root-variable-data-prototype=EE_PEDAL_SENSOR_StrIMM_RamBlock_Core0, target-data-prototype=EE_PEDAL_SENSOR_StrIMM_Ram_Core0/AeAPSR_b_Pv2MinTestFailed}, written-nv-data=AeAPSR_b_Pv2MinTestFailed_Rx.AeAPSR_b_Pv2MinTestFailed}
        {nv-ram-block-element=autosar-variable-in-impl-datatype={root-variable-data-prototype=EE_PEDAL_SENSOR_StrIMM_RamBlock_Core0, target-data-prototype=EE_PEDAL_SENSOR_StrIMM_Ram_Core0/AeAPSR_b_Pv2MaxTestNotCmplt}, read-nv-data=AeAPSR_b_Pv2MaxTestNotCmplt.AeAPSR_b_Pv2MaxTestNotCmplt}
        {nv-ram-block-element=autosar-variable-in-impl-datatype={root-variable-data-prototype=EE_PEDAL_SENSOR_StrIMM_RamBlock_Core0, target-data-prototype=EE_PEDAL_SENSOR_StrIMM_Ram_Core0/AeAPSR_b_Pv2MaxTestNotCmplt}, written-nv-data=AeAPSR_b_Pv2MaxTestNotCmplt_Rx.AeAPSR_b_Pv2MaxTestNotCmplt}
        {nv-ram-block-element=autosar-variable-in-impl-datatype={root-variable-data-prototype=EE_PEDAL_SENSOR_StrIMM_RamBlock_Core0, target-data-prototype=EE_PEDAL_SENSOR_StrIMM_Ram_Core0/AeAPSR_b_Pv2MaxTestFailed}, read-nv-data=AeAPSR_b_Pv2MaxTestFailed.AeAPSR_b_Pv2MaxTestFailed}
        {nv-ram-block-element=autosar-variable-in-impl-datatype={root-variable-data-prototype=EE_PEDAL_SENSOR_StrIMM_RamBlock_Core0, target-data-prototype=EE_PEDAL_SENSOR_StrIMM_Ram_Core0/AeAPSR_b_Pv2MaxTestFailed}, written-nv-data=AeAPSR_b_Pv2MaxTestFailed_Rx.AeAPSR_b_Pv2MaxTestFailed}
        {nv-ram-block-element=autosar-variable-in-impl-datatype={root-variable-data-prototype=EE_PEDAL_SENSOR_StrIMM_RamBlock_Core0, target-data-prototype=EE_PEDAL_SENSOR_StrIMM_Ram_Core0/AeAPSR_b_Pv1MinTestNotCmplt}, read-nv-data=AeAPSR_b_Pv1MinTestNotCmplt.AeAPSR_b_Pv1MinTestNotCmplt}
        {nv-ram-block-element=autosar-variable-in-impl-datatype={root-variable-data-prototype=EE_PEDAL_SENSOR_StrIMM_RamBlock_Core0, target-data-prototype=EE_PEDAL_SENSOR_StrIMM_Ram_Core0/AeAPSR_b_Pv1MinTestNotCmplt}, written-nv-data=AeAPSR_b_Pv1MinTestNotCmplt_Rx.AeAPSR_b_Pv1MinTestNotCmplt}
        {nv-ram-block-element=autosar-variable-in-impl-datatype={root-variable-data-prototype=EE_PEDAL_SENSOR_StrIMM_RamBlock_Core0, target-data-prototype=EE_PEDAL_SENSOR_StrIMM_Ram_Core0/AeAPSR_b_Pv1MinTestFailed}, read-nv-data=AeAPSR_b_Pv1MinTestFailed.AeAPSR_b_Pv1MinTestFailed}
        {nv-ram-block-element=autosar-variable-in-impl-datatype={root-variable-data-prototype=EE_PEDAL_SENSOR_StrIMM_RamBlock_Core0, target-data-prototype=EE_PEDAL_SENSOR_StrIMM_Ram_Core0/AeAPSR_b_Pv1MinTestFailed}, written-nv-data=AeAPSR_b_Pv1MinTestFailed_Rx.AeAPSR_b_Pv1MinTestFailed}
        {nv-ram-block-element=autosar-variable-in-impl-datatype={root-variable-data-prototype=EE_PEDAL_SENSOR_StrIMM_RamBlock_Core0, target-data-prototype=EE_PEDAL_SENSOR_StrIMM_Ram_Core0/AeAPSR_b_Pv1MaxTestNotCmplt}, read-nv-data=AeAPSR_b_Pv1MaxTestNotCmplt.AeAPSR_b_Pv1MaxTestNotCmplt}
        {nv-ram-block-element=autosar-variable-in-impl-datatype={root-variable-data-prototype=EE_PEDAL_SENSOR_StrIMM_RamBlock_Core0, target-data-prototype=EE_PEDAL_SENSOR_StrIMM_Ram_Core0/AeAPSR_b_Pv1MaxTestNotCmplt}, written-nv-data=AeAPSR_b_Pv1MaxTestNotCmplt_Rx.AeAPSR_b_Pv1MaxTestNotCmplt}
        {nv-ram-block-element=autosar-variable-in-impl-datatype={root-variable-data-prototype=EE_PEDAL_SENSOR_StrIMM_RamBlock_Core0, target-data-prototype=EE_PEDAL_SENSOR_StrIMM_Ram_Core0/AeAPSR_b_Pv1MaxTestFailed}, read-nv-data=AeAPSR_b_Pv1MaxTestFailed.AeAPSR_b_Pv1MaxTestFailed}
        {nv-ram-block-element=autosar-variable-in-impl-datatype={root-variable-data-prototype=EE_PEDAL_SENSOR_StrIMM_RamBlock_Core0, target-data-prototype=EE_PEDAL_SENSOR_StrIMM_Ram_Core0/AeAPSR_b_Pv1MaxTestFailed}, written-nv-data=AeAPSR_b_Pv1MaxTestFailed_Rx.AeAPSR_b_Pv1MaxTestFailed}
      nv block needs NvBlockNeeds: calc-ram-block-crc=false, check-static-block-id=false, readonly=false, resistant-to-changed-sw=false, restore-at-start=true, store-at-shutdown=false, store-cyclic=false, store-emergency=false, store-immediate=true, use-auto-validation-at-shut-down=false, use-crc-comp-mechanism=true, write-only-once=false, write-verification=false
      ram block EE_PEDAL_SENSOR_StrIMM_RamBlock_Core0: type=EE_PEDAL_SENSOR_StrIMM_Ram_Core0, init-value={short-label=EE_PEDAL_SENSOR_StrIMM_Ram_Core0, fields=[AeAPSR_U_Pvs1MaxValue:0, AeAPSR_U_Pvs1MinValue:0, AeAPSR_U_Pvs2MaxValue:0, AeAPSR_U_Pvs2MinValue:0, AeAPSR_b_Pv2MinTestNotCmplt:0, AeAPSR_b_Pv2MinTestFailed:0, AeAPSR_b_Pv2MaxTestNotCmplt:0, AeAPSR_b_Pv2MaxTestFailed:0, AeAPSR_b_Pv1MinTestNotCmplt:0, AeAPSR_b_Pv1MinTestFailed:0, AeAPSR_b_Pv1MaxTestNotCmplt:0, AeAPSR_b_Pv1MaxTestFailed:0]}
      rom block EE_PEDAL_SENSOR_StrIMM_RomBlock_Core0: type=EE_PEDAL_SENSOR_StrIMM_Rom_Core0, init-value={short-label=EE_PEDAL_SENSOR_StrIMM_Rom_Core0, fields=[AeAPSR_U_Pvs1MaxValue:0, AeAPSR_U_Pvs1MinValue:0, AeAPSR_U_Pvs2MaxValue:0, AeAPSR_U_Pvs2MinValue:0, AeAPSR_b_Pv2MinTestNotCmplt:0, AeAPSR_b_Pv2MinTestFailed:0, AeAPSR_b_Pv2MaxTestNotCmplt:0, AeAPSR_b_Pv2MaxTestFailed:0, AeAPSR_b_Pv1MinTestNotCmplt:0, AeAPSR_b_Pv1MinTestFailed:0, AeAPSR_b_Pv1MaxTestNotCmplt:0, AeAPSR_b_Pv1MaxTestFailed:0]}
package /IFEepNVBlk_0
  4 x impl type, all with category=STRUCTURE:
    ExpendableNonVolatile_Ram_Core0
      82 x element, all with category=TYPE_REFERENCE:
        NeAPSR_U_Lv1PvAdapt: implementation-data-type=float32
        NeTAIB_Cnt_Fan2CntrlModPerf_MFOP: implementation-data-type=uint16
        NeTRIB_Cnt_HXCTOSSTG_MFOP: implementation-data-type=uint16
        NeTAIB_Cnt_OEXVInTSnsrSTB_MFOP: implementation-data-type=uint16
        NeTAIB_Cnt_HghRfrgtPSnsrSTG_MFOP: implementation-data-type=uint16
        NeTAIB_Cnt_HghRfrgtPSnsrSTB_MFOP: implementation-data-type=uint16
        NeTAIB_Cnt_Fan2UnderSpeed_MFOP: implementation-data-type=uint16
        NeTAIB_Cnt_Fan2StuckOff_MFOP: implementation-data-type=uint16
        NeTRIB_Cnt_HRCTOSSTG_MFOP: implementation-data-type=uint16
        NeTRIB_Cnt_HXCTOSSTB_MFOP: implementation-data-type=uint16
        NeTRIB_Cnt_HRCTOSSTB_MFOP: implementation-data-type=uint16
        NeTRIB_Cnt_HRCTISSTG_MFOP: implementation-data-type=uint16
        NeTAIB_Cnt_RadFanErrM2_MFOP: implementation-data-type=uint16
        NeTAIB_Cnt_RadFanErrM1_MFOP: implementation-data-type=uint16
        NeTAIB_Cnt_RadFanErrM0_MFOP: implementation-data-type=uint16
        NeTRIB_Cnt_HRCTISSTB_MFOP: implementation-data-type=uint16
        NeTAIB_Cnt_OEXVInTSnsrSTG_MFOP: implementation-data-type=uint16
        NeTAIB_Cnt_5VAux1_MFOP: implementation-data-type=uint16
        NePMDB_Cnt_BpcmWakeupSTG_MFOP: implementation-data-type=uint16
        NePMDB_Cnt_BpcmWakeupSTB_MFOP: implementation-data-type=uint16
        NePMIB_Cnt_EleclOilPmpSpdFb_MFOP: implementation-data-type=uint16
        NeTMIB_Cnt_PPCTISSTG_MFOP: implementation-data-type=uint16
        NeTMIB_Cnt_ECHTISSTG_MFOP: implementation-data-type=uint16
        NeTMIB_Cnt_PECTOSSTB_MFOP: implementation-data-type=uint16
        NeTMIB_Cnt_PECTOSSTG_MFOP: implementation-data-type=uint16
        NeTMIB_Cnt_PPCTISSTB_MFOP: implementation-data-type=uint16
        NeTMIB_Cnt_ECHTISSTB_MFOP: implementation-data-type=uint16
        NeTRIB_Cnt_BTISSTB_MFOP: implementation-data-type=uint16
        NeTRIB_Cnt_HCCTOSSTG_MFOP: implementation-data-type=uint16
        NeTRIB_Cnt_HCCTOSSTB_MFOP: implementation-data-type=uint16
        NeTRIB_Cnt_HCCTISSTG_MFOP: implementation-data-type=uint16
        NeTRIB_Cnt_BTISSTG_MFOP: implementation-data-type=uint16
        NeTRIB_Cnt_BTOSSTB_MFOP: implementation-data-type=uint16
        NeTRIB_Cnt_HCCTISSTB_MFOP: implementation-data-type=uint16
        NeTRIB_Cnt_BTOSSTG_MFOP: implementation-data-type=uint16
        NeTRIB_Cnt_BatClntSnsSTG_MFOP: implementation-data-type=uint16
        NeDMIB_Cnt_PadLvrSTG_MFOP: implementation-data-type=uint16
        NeDMIB_Cnt_PadLvrSTB_MFOP: implementation-data-type=uint16
        NeADFB_Cnt_A2DFault_MFOP: implementation-data-type=uint16
        NeNVMB_Cnt_RadFan2CtrlSTG_MFOP: implementation-data-type=uint16
        NeNVMB_Cnt_STGFtRfgtShtOffVlv_MFOP: implementation-data-type=uint16
        NeNVMB_Cnt_STBFtRfgtShtOffVlv_MFOP: implementation-data-type=uint16
        NeNVMB_Cnt_RadrFanCtrlSTG_MFOP: implementation-data-type=uint16
        NeNVMB_Cnt_RadrFanCtrlSTB_MFOP: implementation-data-type=uint16
        NeNVMB_Cnt_RadFan2CtrlSTB_MFOP: implementation-data-type=uint16
        NeNVMB_Cnt_RadFan2CtrlOC_MFOP: implementation-data-type=uint16
        NeNVMB_Cnt_ePTWakeUpEnblOC_MFOP: implementation-data-type=uint16
        NeNVMB_Cnt_ePTWakeUpEnblSTB_MFOP: implementation-data-type=uint16
        NeNVMB_Cnt_ePTWakeUpEnblSTG_MFOP: implementation-data-type=uint16
        NeNVMB_Cnt_FtRfgtShtOffVlvOC_MFOP: implementation-data-type=uint16
        NeNVMB_Cnt_ThermSysEnbl_MFOP: implementation-data-type=uint16
        NeNVMB_Cnt_RadrFanCtrlOC_MFOP: implementation-data-type=uint16
        NeBSWR_e_ShutOffPathTestStatus_prev: implementation-data-type=uint8
        NeSPT_SkippedOccurenceCounter: implementation-data-type=uint8
        NeSPT_AttemptsCounter: implementation-data-type=uint8
        Reserved{1..27}: implementation-data-type=uint8
    ExpendableNonVolatile_Rom_Core0
      82 x element, all with category=TYPE_REFERENCE:
        NeAPSR_U_Lv1PvAdapt: implementation-data-type=float32
        NeTAIB_Cnt_Fan2CntrlModPerf_MFOP: implementation-data-type=uint16
        NeTRIB_Cnt_HXCTOSSTG_MFOP: implementation-data-type=uint16
        NeTAIB_Cnt_OEXVInTSnsrSTB_MFOP: implementation-data-type=uint16
        NeTAIB_Cnt_HghRfrgtPSnsrSTG_MFOP: implementation-data-type=uint16
        NeTAIB_Cnt_HghRfrgtPSnsrSTB_MFOP: implementation-data-type=uint16
        NeTAIB_Cnt_Fan2UnderSpeed_MFOP: implementation-data-type=uint16
        NeTAIB_Cnt_Fan2StuckOff_MFOP: implementation-data-type=uint16
        NeTRIB_Cnt_HRCTOSSTG_MFOP: implementation-data-type=uint16
        NeTRIB_Cnt_HXCTOSSTB_MFOP: implementation-data-type=uint16
        NeTRIB_Cnt_HRCTOSSTB_MFOP: implementation-data-type=uint16
        NeTRIB_Cnt_HRCTISSTG_MFOP: implementation-data-type=uint16
        NeTAIB_Cnt_RadFanErrM2_MFOP: implementation-data-type=uint16
        NeTAIB_Cnt_RadFanErrM1_MFOP: implementation-data-type=uint16
        NeTAIB_Cnt_RadFanErrM0_MFOP: implementation-data-type=uint16
        NeTRIB_Cnt_HRCTISSTB_MFOP: implementation-data-type=uint16
        NeTAIB_Cnt_OEXVInTSnsrSTG_MFOP: implementation-data-type=uint16
        NeTAIB_Cnt_5VAux1_MFOP: implementation-data-type=uint16
        NePMDB_Cnt_BpcmWakeupSTG_MFOP: implementation-data-type=uint16
        NePMDB_Cnt_BpcmWakeupSTB_MFOP: implementation-data-type=uint16
        NePMIB_Cnt_EleclOilPmpSpdFb_MFOP: implementation-data-type=uint16
        NeTMIB_Cnt_PPCTISSTG_MFOP: implementation-data-type=uint16
        NeTMIB_Cnt_ECHTISSTG_MFOP: implementation-data-type=uint16
        NeTMIB_Cnt_PECTOSSTB_MFOP: implementation-data-type=uint16
        NeTMIB_Cnt_PECTOSSTG_MFOP: implementation-data-type=uint16
        NeTMIB_Cnt_PPCTISSTB_MFOP: implementation-data-type=uint16
        NeTMIB_Cnt_ECHTISSTB_MFOP: implementation-data-type=uint16
        NeTRIB_Cnt_BTISSTB_MFOP: implementation-data-type=uint16
        NeTRIB_Cnt_HCCTOSSTG_MFOP: implementation-data-type=uint16
        NeTRIB_Cnt_HCCTOSSTB_MFOP: implementation-data-type=uint16
        NeTRIB_Cnt_HCCTISSTG_MFOP: implementation-data-type=uint16
        NeTRIB_Cnt_BTISSTG_MFOP: implementation-data-type=uint16
        NeTRIB_Cnt_BTOSSTB_MFOP: implementation-data-type=uint16
        NeTRIB_Cnt_HCCTISSTB_MFOP: implementation-data-type=uint16
        NeTRIB_Cnt_BTOSSTG_MFOP: implementation-data-type=uint16
        NeTRIB_Cnt_BatClntSnsSTG_MFOP: implementation-data-type=uint16
        NeDMIB_Cnt_PadLvrSTG_MFOP: implementation-data-type=uint16
        NeDMIB_Cnt_PadLvrSTB_MFOP: implementation-data-type=uint16
        NeADFB_Cnt_A2DFault_MFOP: implementation-data-type=uint16
        NeNVMB_Cnt_RadFan2CtrlSTG_MFOP: implementation-data-type=uint16
        NeNVMB_Cnt_STGFtRfgtShtOffVlv_MFOP: implementation-data-type=uint16
        NeNVMB_Cnt_STBFtRfgtShtOffVlv_MFOP: implementation-data-type=uint16
        NeNVMB_Cnt_RadrFanCtrlSTG_MFOP: implementation-data-type=uint16
        NeNVMB_Cnt_RadrFanCtrlSTB_MFOP: implementation-data-type=uint16
        NeNVMB_Cnt_RadFan2CtrlSTB_MFOP: implementation-data-type=uint16
        NeNVMB_Cnt_RadFan2CtrlOC_MFOP: implementation-data-type=uint16
        NeNVMB_Cnt_ePTWakeUpEnblOC_MFOP: implementation-data-type=uint16
        NeNVMB_Cnt_ePTWakeUpEnblSTB_MFOP: implementation-data-type=uint16
        NeNVMB_Cnt_ePTWakeUpEnblSTG_MFOP: implementation-data-type=uint16
        NeNVMB_Cnt_FtRfgtShtOffVlvOC_MFOP: implementation-data-type=uint16
        NeNVMB_Cnt_ThermSysEnbl_MFOP: implementation-data-type=uint16
        NeNVMB_Cnt_RadrFanCtrlOC_MFOP: implementation-data-type=uint16
        NeBSWR_e_ShutOffPathTestStatus_prev: implementation-data-type=uint8
        NeSPT_SkippedOccurenceCounter: implementation-data-type=uint8
        NeSPT_AttemptsCounter: implementation-data-type=uint8
        Reserved{1..27}: implementation-data-type=uint8
    EE_PEDAL_SENSOR_StrIMM_Ram_Core0
      12 x element, all with category=TYPE_REFERENCE:
        AeAPSR_U_Pvs1MaxValue: implementation-data-type=float32
        AeAPSR_U_Pvs1MinValue: implementation-data-type=float32
        AeAPSR_U_Pvs2MaxValue: implementation-data-type=float32
        AeAPSR_U_Pvs2MinValue: implementation-data-type=float32
        AeAPSR_b_Pv2MinTestNotCmplt: implementation-data-type=boolean
        AeAPSR_b_Pv2MinTestFailed: implementation-data-type=boolean
        AeAPSR_b_Pv2MaxTestNotCmplt: implementation-data-type=boolean
        AeAPSR_b_Pv2MaxTestFailed: implementation-data-type=boolean
        AeAPSR_b_Pv1MinTestNotCmplt: implementation-data-type=boolean
        AeAPSR_b_Pv1MinTestFailed: implementation-data-type=boolean
        AeAPSR_b_Pv1MaxTestNotCmplt: implementation-data-type=boolean
        AeAPSR_b_Pv1MaxTestFailed: implementation-data-type=boolean
    EE_PEDAL_SENSOR_StrIMM_Rom_Core0
      12 x element, all with category=TYPE_REFERENCE:
        AeAPSR_U_Pvs1MaxValue: implementation-data-type=float32
        AeAPSR_U_Pvs1MinValue: implementation-data-type=float32
        AeAPSR_U_Pvs2MaxValue: implementation-data-type=float32
        AeAPSR_U_Pvs2MinValue: implementation-data-type=float32
        AeAPSR_b_Pv2MinTestNotCmplt: implementation-data-type=boolean
        AeAPSR_b_Pv2MinTestFailed: implementation-data-type=boolean
        AeAPSR_b_Pv2MaxTestNotCmplt: implementation-data-type=boolean
        AeAPSR_b_Pv2MaxTestFailed: implementation-data-type=boolean
        AeAPSR_b_Pv1MinTestNotCmplt: implementation-data-type=boolean
        AeAPSR_b_Pv1MinTestFailed: implementation-data-type=boolean
        AeAPSR_b_Pv1MaxTestNotCmplt: implementation-data-type=boolean
        AeAPSR_b_Pv1MaxTestFailed: implementation-data-type=boolean
